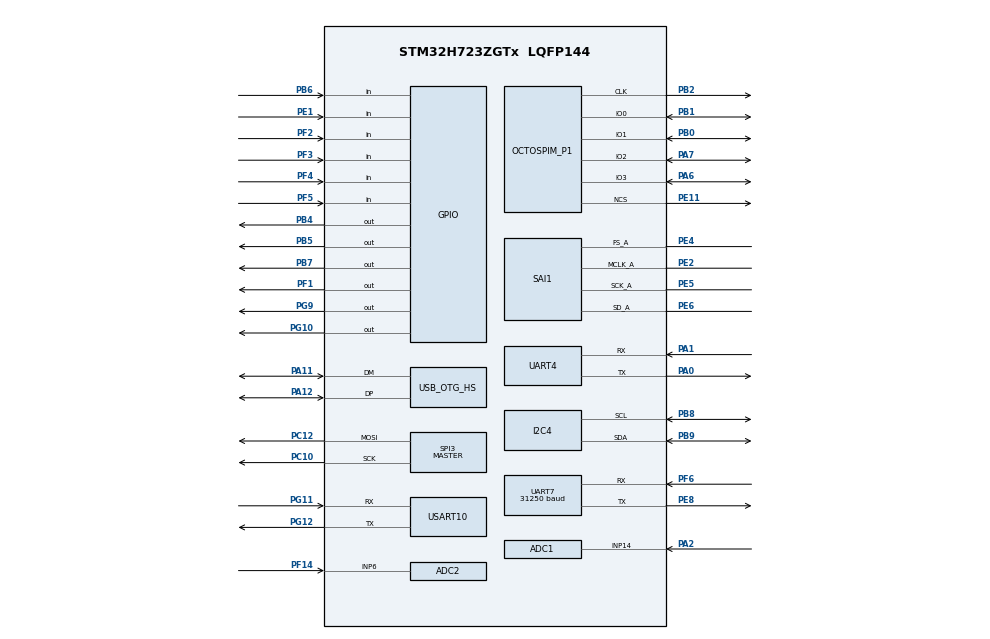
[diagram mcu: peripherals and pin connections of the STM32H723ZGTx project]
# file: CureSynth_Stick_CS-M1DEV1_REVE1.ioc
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ADC1.Channel-0\#ChannelRegularConversion=ADC_CHANNEL_14
ADC1.ClockPrescaler=ADC_CLOCK_ASYNC_DIV8
ADC1.ContinuousConvMode=ENABLE
ADC1.ConversionDataManagement=ADC_CONVERSIONDATA_DMA_CIRCULAR
ADC1.NbrOfConversionFlag=1
ADC1.OffsetNumber-0\#ChannelRegularConversion=ADC_OFFSET_NONE
ADC1.OffsetSignedSaturation-0\#ChannelRegularConversion=DISABLE
ADC1.OversamplingMode=ENABLE
ADC1.Rank-0\#ChannelRegularConversion=1
ADC1.Ratio=16
ADC1.Resolution=ADC_RESOLUTION_12B
ADC1.RightBitShift=ADC_RIGHTBITSHIFT_4
ADC1.SamplingTime-0\#ChannelRegularConversion=ADC_SAMPLETIME_387CYCLES_5
ADC1.master=1
ADC2.Channel-1\#ChannelRegularConversion=ADC_CHANNEL_6
ADC2.ClockPrescaler=ADC_CLOCK_ASYNC_DIV8
ADC2.ContinuousConvMode=ENABLE
ADC2.ConversionDataManagement=ADC_CONVERSIONDATA_DMA_CIRCULAR
ADC2.NbrOfConversionFlag=1
ADC2.OffsetNumber-1\#ChannelRegularConversion=ADC_OFFSET_NONE
ADC2.OffsetSignedSaturation-1\#ChannelRegularConversion=DISABLE
ADC2.OversamplingMode=ENABLE
ADC2.Rank-1\#ChannelRegularConversion=1
ADC2.Ratio=16
ADC2.Resolution=ADC_RESOLUTION_12B
ADC2.RightBitShift=ADC_RIGHTBITSHIFT_4
ADC2.SamplingTime-1\#ChannelRegularConversion=ADC_SAMPLETIME_387CYCLES_5
CORTEX_M7.CPU_DCache=Enabled
CORTEX_M7.CPU_ICache=Enabled
Dma.ADC1.3.Direction=DMA_PERIPH_TO_MEMORY
Dma.ADC1.3.EventEnable=DISABLE
Dma.ADC1.3.FIFOMode=DMA_FIFOMODE_DISABLE
Dma.ADC1.3.Instance=DMA1_Stream2
Dma.ADC1.3.MemDataAlignment=DMA_MDATAALIGN_HALFWORD
Dma.ADC1.3.MemInc=DMA_MINC_ENABLE
Dma.ADC1.3.Mode=DMA_CIRCULAR
Dma.ADC1.3.PeriphDataAlignment=DMA_PDATAALIGN_HALFWORD
Dma.ADC1.3.PeriphInc=DMA_PINC_DISABLE
Dma.ADC1.3.Polarity=HAL_DMAMUX_REQ_GEN_RISING
Dma.ADC1.3.Priority=DMA_PRIORITY_LOW
Dma.ADC1.3.RequestNumber=1
Dma.ADC1.3.SignalID=NONE
Dma.ADC1.3.SyncEnable=DISABLE
Dma.ADC1.3.SyncPolarity=HAL_DMAMUX_SYNC_NO_EVENT
Dma.ADC1.3.SyncRequestNumber=1
Dma.ADC1.3.SyncSignalID=NONE
Dma.ADC2.2.Direction=DMA_PERIPH_TO_MEMORY
Dma.ADC2.2.EventEnable=DISABLE
Dma.ADC2.2.FIFOMode=DMA_FIFOMODE_DISABLE
Dma.ADC2.2.Instance=DMA1_Stream1
Dma.ADC2.2.MemDataAlignment=DMA_MDATAALIGN_HALFWORD
Dma.ADC2.2.MemInc=DMA_MINC_ENABLE
Dma.ADC2.2.Mode=DMA_CIRCULAR
Dma.ADC2.2.PeriphDataAlignment=DMA_PDATAALIGN_HALFWORD
Dma.ADC2.2.PeriphInc=DMA_PINC_DISABLE
Dma.ADC2.2.Polarity=HAL_DMAMUX_REQ_GEN_RISING
Dma.ADC2.2.Priority=DMA_PRIORITY_LOW
Dma.ADC2.2.RequestNumber=1
Dma.ADC2.2.SignalID=NONE
Dma.ADC2.2.SyncEnable=DISABLE
Dma.ADC2.2.SyncPolarity=HAL_DMAMUX_SYNC_NO_EVENT
Dma.ADC2.2.SyncRequestNumber=1
Dma.ADC2.2.SyncSignalID=NONE
Dma.MEMTOMEM.4.Direction=DMA_MEMORY_TO_MEMORY
Dma.MEMTOMEM.4.EventEnable=DISABLE
Dma.MEMTOMEM.4.FIFOMode=DMA_FIFOMODE_ENABLE
Dma.MEMTOMEM.4.FIFOThreshold=DMA_FIFO_THRESHOLD_HALFFULL
Dma.MEMTOMEM.4.Instance=DMA1_Stream0
Dma.MEMTOMEM.4.MemBurst=DMA_MBURST_SINGLE
Dma.MEMTOMEM.4.MemDataAlignment=DMA_MDATAALIGN_BYTE
Dma.MEMTOMEM.4.MemInc=DMA_MINC_ENABLE
Dma.MEMTOMEM.4.Mode=DMA_NORMAL
Dma.MEMTOMEM.4.PeriphBurst=DMA_PBURST_SINGLE
Dma.MEMTOMEM.4.PeriphDataAlignment=DMA_PDATAALIGN_BYTE
Dma.MEMTOMEM.4.PeriphInc=DMA_PINC_ENABLE
Dma.MEMTOMEM.4.Polarity=HAL_DMAMUX_REQ_GEN_RISING
Dma.MEMTOMEM.4.Priority=DMA_PRIORITY_MEDIUM
Dma.MEMTOMEM.4.RequestNumber=1
Dma.MEMTOMEM.4.SignalID=NONE
Dma.MEMTOMEM.4.SyncEnable=DISABLE
Dma.MEMTOMEM.4.SyncPolarity=HAL_DMAMUX_SYNC_NO_EVENT
Dma.MEMTOMEM.4.SyncRequestNumber=1
Dma.MEMTOMEM.4.SyncSignalID=NONE
Dma.MEMTOMEM.5.Direction=DMA_MEMORY_TO_MEMORY
Dma.MEMTOMEM.5.EventEnable=DISABLE
Dma.MEMTOMEM.5.FIFOMode=DMA_FIFOMODE_ENABLE
Dma.MEMTOMEM.5.FIFOThreshold=DMA_FIFO_THRESHOLD_HALFFULL
Dma.MEMTOMEM.5.Instance=DMA1_Stream3
Dma.MEMTOMEM.5.MemBurst=DMA_MBURST_SINGLE
Dma.MEMTOMEM.5.MemDataAlignment=DMA_MDATAALIGN_BYTE
Dma.MEMTOMEM.5.MemInc=DMA_MINC_ENABLE
Dma.MEMTOMEM.5.Mode=DMA_NORMAL
Dma.MEMTOMEM.5.PeriphBurst=DMA_PBURST_SINGLE
Dma.MEMTOMEM.5.PeriphDataAlignment=DMA_PDATAALIGN_BYTE
Dma.MEMTOMEM.5.PeriphInc=DMA_PINC_ENABLE
Dma.MEMTOMEM.5.Polarity=HAL_DMAMUX_REQ_GEN_RISING
Dma.MEMTOMEM.5.Priority=DMA_PRIORITY_MEDIUM
Dma.MEMTOMEM.5.RequestNumber=1
Dma.MEMTOMEM.5.SignalID=NONE
Dma.MEMTOMEM.5.SyncEnable=DISABLE
Dma.MEMTOMEM.5.SyncPolarity=HAL_DMAMUX_SYNC_NO_EVENT
Dma.MEMTOMEM.5.SyncRequestNumber=1
Dma.MEMTOMEM.5.SyncSignalID=NONE
Dma.Request0=SPI3_TX
Dma.Request1=SAI1_A
Dma.Request2=ADC2
Dma.Request3=ADC1
Dma.Request4=MEMTOMEM
Dma.Request5=MEMTOMEM
Dma.Request6=UART7_RX
Dma.SAI1_A.1.Direction=DMA_MEMORY_TO_PERIPH
Dma.SAI1_A.1.EventEnable=DISABLE
Dma.SAI1_A.1.FIFOMode=DMA_FIFOMODE_DISABLE
Dma.SAI1_A.1.Instance=DMA2_Stream6
Dma.SAI1_A.1.MemDataAlignment=DMA_MDATAALIGN_HALFWORD
Dma.SAI1_A.1.MemInc=DMA_MINC_ENABLE
Dma.SAI1_A.1.Mode=DMA_CIRCULAR
Dma.SAI1_A.1.PeriphDataAlignment=DMA_PDATAALIGN_HALFWORD
Dma.SAI1_A.1.PeriphInc=DMA_PINC_DISABLE
Dma.SAI1_A.1.Polarity=HAL_DMAMUX_REQ_GEN_RISING
Dma.SAI1_A.1.Priority=DMA_PRIORITY_MEDIUM
Dma.SAI1_A.1.RequestNumber=1
Dma.SAI1_A.1.SignalID=NONE
Dma.SAI1_A.1.SyncEnable=DISABLE
Dma.SAI1_A.1.SyncPolarity=HAL_DMAMUX_SYNC_NO_EVENT
Dma.SAI1_A.1.SyncRequestNumber=1
Dma.SAI1_A.1.SyncSignalID=NONE
Dma.SPI3_TX.0.Direction=DMA_MEMORY_TO_PERIPH
Dma.SPI3_TX.0.EventEnable=DISABLE
Dma.SPI3_TX.0.FIFOMode=DMA_FIFOMODE_ENABLE
Dma.SPI3_TX.0.FIFOThreshold=DMA_FIFO_THRESHOLD_FULL
Dma.SPI3_TX.0.Instance=DMA1_Stream5
Dma.SPI3_TX.0.MemBurst=DMA_MBURST_SINGLE
Dma.SPI3_TX.0.MemDataAlignment=DMA_MDATAALIGN_HALFWORD
Dma.SPI3_TX.0.MemInc=DMA_MINC_ENABLE
Dma.SPI3_TX.0.Mode=DMA_NORMAL
Dma.SPI3_TX.0.PeriphBurst=DMA_PBURST_SINGLE
Dma.SPI3_TX.0.PeriphDataAlignment=DMA_PDATAALIGN_HALFWORD
Dma.SPI3_TX.0.PeriphInc=DMA_PINC_DISABLE
Dma.SPI3_TX.0.Polarity=HAL_DMAMUX_REQ_GEN_RISING
Dma.SPI3_TX.0.Priority=DMA_PRIORITY_LOW
Dma.SPI3_TX.0.RequestNumber=1
Dma.SPI3_TX.0.SignalID=NONE
Dma.SPI3_TX.0.SyncEnable=DISABLE
Dma.SPI3_TX.0.SyncPolarity=HAL_DMAMUX_SYNC_NO_EVENT
Dma.SPI3_TX.0.SyncRequestNumber=1
Dma.SPI3_TX.0.SyncSignalID=NONE
Dma.UART7_RX.6.Direction=DMA_PERIPH_TO_MEMORY
Dma.UART7_RX.6.EventEnable=DISABLE
Dma.UART7_RX.6.FIFOMode=DMA_FIFOMODE_DISABLE
Dma.UART7_RX.6.Instance=DMA1_Stream4
Dma.UART7_RX.6.MemDataAlignment=DMA_MDATAALIGN_BYTE
Dma.UART7_RX.6.MemInc=DMA_MINC_ENABLE
Dma.UART7_RX.6.Mode=DMA_NORMAL
Dma.UART7_RX.6.PeriphDataAlignment=DMA_PDATAALIGN_BYTE
Dma.UART7_RX.6.PeriphInc=DMA_PINC_DISABLE
Dma.UART7_RX.6.Polarity=HAL_DMAMUX_REQ_GEN_RISING
Dma.UART7_RX.6.Priority=DMA_PRIORITY_LOW
Dma.UART7_RX.6.RequestNumber=1
Dma.UART7_RX.6.SignalID=NONE
Dma.UART7_RX.6.SyncEnable=DISABLE
Dma.UART7_RX.6.SyncPolarity=HAL_DMAMUX_SYNC_NO_EVENT
Dma.UART7_RX.6.SyncRequestNumber=1
Dma.UART7_RX.6.SyncSignalID=NONE
I2C4.Speed=80
I2C4.Timing=0x60404DA4
IWDG1.Prescaler=IWDG_PRESCALER_16
Mcu.Family=STM32H7
Mcu.Name=STM32H723ZGTx
Mcu.Package=LQFP144
Mdma.MDMA_Channel0.DMA1_Stream0_TC.0.BlockCount=0
Mdma.MDMA_Channel0.DMA1_Stream0_TC.0.BlockDataLength=0
Mdma.MDMA_Channel0.DMA1_Stream0_TC.0.BufferTransferLength=1
Mdma.MDMA_Channel0.DMA1_Stream0_TC.0.CircularMode=MDMA_LINEAR_LIST
Mdma.MDMA_Channel0.DMA1_Stream0_TC.0.DataAlignment=MDMA_DATAALIGN_PACKENABLE
Mdma.MDMA_Channel0.DMA1_Stream0_TC.0.DestBlockAddressOffset=0
Mdma.MDMA_Channel0.DMA1_Stream0_TC.0.DestBurst=MDMA_DEST_BURST_SINGLE
Mdma.MDMA_Channel0.DMA1_Stream0_TC.0.DestDataSize=MDMA_DEST_DATASIZE_BYTE
Mdma.MDMA_Channel0.DMA1_Stream0_TC.0.DestinationInc=MDMA_DEST_INC_BYTE
Mdma.MDMA_Channel0.DMA1_Stream0_TC.0.DstAddress=0
Mdma.MDMA_Channel0.DMA1_Stream0_TC.0.Endianness=MDMA_LITTLE_ENDIANNESS_PRESERVE
Mdma.MDMA_Channel0.DMA1_Stream0_TC.0.Instance=MDMA_Channel0
Mdma.MDMA_Channel0.DMA1_Stream0_TC.0.MaskAddress=0
Mdma.MDMA_Channel0.DMA1_Stream0_TC.0.MaskData=0
Mdma.MDMA_Channel0.DMA1_Stream0_TC.0.Priority=MDMA_PRIORITY_LOW
Mdma.MDMA_Channel0.DMA1_Stream0_TC.0.Rank=First
Mdma.MDMA_Channel0.DMA1_Stream0_TC.0.SourceBlockAddressOffset=0
Mdma.MDMA_Channel0.DMA1_Stream0_TC.0.SourceBurst=MDMA_SOURCE_BURST_SINGLE
Mdma.MDMA_Channel0.DMA1_Stream0_TC.0.SourceDataSize=MDMA_SRC_DATASIZE_BYTE
Mdma.MDMA_Channel0.DMA1_Stream0_TC.0.SourceInc=MDMA_SRC_INC_BYTE
Mdma.MDMA_Channel0.DMA1_Stream0_TC.0.SrcAddress=0
Mdma.MDMA_Channel0.DMA1_Stream0_TC.0.TransferTriggerMode=MDMA_BUFFER_TRANSFER
Mdma.MDMA_Channel0.DMA1_Stream3_TC.1.BlockCount=0
Mdma.MDMA_Channel0.DMA1_Stream3_TC.1.BlockDataLength=0
Mdma.MDMA_Channel0.DMA1_Stream3_TC.1.BufferTransferLength=1
Mdma.MDMA_Channel0.DMA1_Stream3_TC.1.CircularMode=MDMA_LINEAR_LIST
Mdma.MDMA_Channel0.DMA1_Stream3_TC.1.DataAlignment=MDMA_DATAALIGN_PACKENABLE
Mdma.MDMA_Channel0.DMA1_Stream3_TC.1.DestBlockAddressOffset=0
Mdma.MDMA_Channel0.DMA1_Stream3_TC.1.DestBurst=MDMA_DEST_BURST_SINGLE
Mdma.MDMA_Channel0.DMA1_Stream3_TC.1.DestDataSize=MDMA_DEST_DATASIZE_BYTE
Mdma.MDMA_Channel0.DMA1_Stream3_TC.1.DestinationInc=MDMA_DEST_INC_BYTE
Mdma.MDMA_Channel0.DMA1_Stream3_TC.1.DstAddress=0
Mdma.MDMA_Channel0.DMA1_Stream3_TC.1.Endianness=MDMA_LITTLE_ENDIANNESS_PRESERVE
Mdma.MDMA_Channel0.DMA1_Stream3_TC.1.Instance=MDMA_Channel0
Mdma.MDMA_Channel0.DMA1_Stream3_TC.1.MaskAddress=0
Mdma.MDMA_Channel0.DMA1_Stream3_TC.1.MaskData=0
Mdma.MDMA_Channel0.DMA1_Stream3_TC.1.Priority=MDMA_PRIORITY_LOW
Mdma.MDMA_Channel0.DMA1_Stream3_TC.1.Rank=Last
Mdma.MDMA_Channel0.DMA1_Stream3_TC.1.SourceBlockAddressOffset=0
Mdma.MDMA_Channel0.DMA1_Stream3_TC.1.SourceBurst=MDMA_SOURCE_BURST_SINGLE
Mdma.MDMA_Channel0.DMA1_Stream3_TC.1.SourceDataSize=MDMA_SRC_DATASIZE_BYTE
Mdma.MDMA_Channel0.DMA1_Stream3_TC.1.SourceInc=MDMA_SRC_INC_BYTE
Mdma.MDMA_Channel0.DMA1_Stream3_TC.1.SrcAddress=0
Mdma.MDMA_Channel0.DMA1_Stream3_TC.1.TransferTriggerMode=MDMA_BUFFER_TRANSFER
Mdma.MDMA_Channel0.DMA1_Stream3_TC.1.node=node_mdma_channel40_dma1_stream3_tc_1
Mdma.MDMA_Channel0.DMA1_Stream3_TC.1.pNewNode=node_mdma_channel40_dma1_stream3_tc_1
Mdma.MDMA_Channel0.Request0=DMA1_Stream0_TC
Mdma.MDMA_Channel0.Request1=DMA1_Stream3_TC
Mdma.MDMA_Channel0.RequestsNb=2
Mdma.RequestSet0=MDMA_Channel0
Mdma.RequestSetsNb=1
NVIC.DMA1_Stream1_IRQn=true\:3\:0\:true\:false\:true\:false\:true\:true
NVIC.DMA1_Stream2_IRQn=true\:3\:0\:true\:false\:true\:false\:true\:true
NVIC.DMA1_Stream4_IRQn=true\:0\:0\:false\:false\:true\:false\:true\:true
NVIC.DMA1_Stream5_IRQn=true\:0\:0\:false\:false\:true\:false\:true\:true
NVIC.DMA2_Stream6_IRQn=true\:0\:0\:false\:false\:true\:false\:true\:true
NVIC.I2C4_EV_IRQn=true\:3\:0\:true\:false\:true\:true\:true\:true
NVIC.MDMA_IRQn=true\:0\:0\:false\:false\:true\:false\:true\:true
NVIC.OTG_HS_IRQn=true\:0\:0\:false\:false\:true\:false\:true\:true
NVIC.PriorityGroup=NVIC_PRIORITYGROUP_2
NVIC.SPI3_IRQn=true\:0\:0\:false\:false\:true\:true\:true\:true
NVIC.TIM16_IRQn=true\:1\:1\:true\:false\:true\:true\:true\:true
NVIC.TIM17_IRQn=true\:0\:1\:false\:false\:true\:true\:true\:true
NVIC.TIM6_DAC_IRQn=true\:0\:2\:false\:false\:true\:true\:true\:true
NVIC.TIM7_IRQn=true\:0\:2\:false\:false\:true\:true\:true\:true
NVIC.UART7_IRQn=true\:0\:2\:false\:false\:true\:true\:true\:true
OCTOSPI1.ChipSelectHighTime=3
OCTOSPI1.ClockPrescaler=1
OCTOSPI1.DeviceSize=21
OCTOSPI1.FifoThreshold=1
OCTOSPI1.Refresh=10
OCTOSPI1.SampleShifting=HAL_OSPI_SAMPLE_SHIFTING_HALFCYCLE
PA0.Mode=Asynchronous
PA0.Signal=UART4_TX
PA1.Mode=Asynchronous
PA1.Signal=UART4_RX
PA11.Mode=Device_Only_FS
PA11.Signal=USB_OTG_HS_DM
PA12.Mode=Device_Only_FS
PA12.Signal=USB_OTG_HS_DP
PA13(JTMS/SWDIO).Mode=Trace_Asynchronous_SW
PA13(JTMS/SWDIO).Signal=DEBUG_JTMS-SWDIO
PA14(JTCK/SWCLK).Mode=Trace_Asynchronous_SW
PA14(JTCK/SWCLK).Signal=DEBUG_JTCK-SWCLK
PA2.Signal=ADCx_INP14
PA6.GPIO_PuPd=GPIO_PULLDOWN
PA6.Mode=OCTOSPI1_IOL_Port1L
PA6.Signal=OCTOSPIM_P1_IO3
PA7.GPIO_PuPd=GPIO_PULLDOWN
PA7.Mode=OCTOSPI1_IOL_Port1L
PA7.Signal=OCTOSPIM_P1_IO2
PB0.GPIO_PuPd=GPIO_PULLDOWN
PB0.Mode=OCTOSPI1_IOL_Port1L
PB0.Signal=OCTOSPIM_P1_IO1
PB1.GPIO_PuPd=GPIO_PULLDOWN
PB1.Mode=OCTOSPI1_IOL_Port1L
PB1.Signal=OCTOSPIM_P1_IO0
PB2.GPIO_PuPd=GPIO_PULLDOWN
PB2.GPIO_Speed_High_Default=GPIO_SPEED_FREQ_HIGH
PB2.Mode=O1_P1_CLK
PB2.Signal=OCTOSPIM_P1_CLK
PB3(JTDO/TRACESWO).Mode=Trace_Asynchronous_SW
PB3(JTDO/TRACESWO).Signal=DEBUG_JTDO-SWO
PB4(NJTRST).GPIO_PuPd=GPIO_PULLDOWN
PB4(NJTRST).Signal=GPIO_Output
PB5.Signal=GPIO_Output
PB6.Signal=GPIO_Input
PB7.Signal=GPIO_Output
PB8.GPIO_Pu=GPIO_PULLUP
PB8.GPIO_PuPd=GPIO_PULLUP
PB8.GPIO_Speed=GPIO_SPEED_FREQ_MEDIUM
PB8.Mode=I2C
PB8.Signal=I2C4_SCL
PB9.GPIO_Pu=GPIO_PULLUP
PB9.GPIO_PuPd=GPIO_PULLUP
PB9.GPIO_Speed=GPIO_SPEED_FREQ_MEDIUM
PB9.Mode=I2C
PB9.Signal=I2C4_SDA
PC10.GPIO_PuPd=GPIO_NOPULL
PC10.GPIO_Speed=GPIO_SPEED_FREQ_VERY_HIGH
PC10.Mode=TX_Only_Simplex_Unidirect_Master
PC10.Signal=SPI3_SCK
PC12.GPIO_PuPd=GPIO_NOPULL
PC12.GPIO_Speed=GPIO_SPEED_FREQ_VERY_HIGH
PC12.Mode=TX_Only_Simplex_Unidirect_Master
PC12.Signal=SPI3_MOSI
PE1.Signal=GPIO_Input
PE11.GPIO_PuPd=GPIO_PULLUP
PE11.Mode=OCTOSPI1_Port1_NCS
PE11.Signal=OCTOSPIM_P1_NCS
PE2.Mode=SAI_A_MasterWithClock
PE2.Signal=SAI1_MCLK_A
PE4.Mode=SAI_A_MasterWithClock
PE4.Signal=SAI1_FS_A
PE5.GPIO_PuPd=GPIO_PULLDOWN
PE5.Mode=SAI_A_MasterWithClock
PE5.Signal=SAI1_SCK_A
PE6.Mode=SAI_A_MasterWithClock
PE6.Signal=SAI1_SD_A
PE8.Mode=Asynchronous
PE8.Signal=UART7_TX
PF1.Signal=GPIO_Output
PF14.Mode=IN6-Single-Ended
PF14.Signal=ADC2_INP6
PF2.Signal=GPIO_Input
PF3.Signal=GPIO_Input
PF4.Signal=GPIO_Input
PF5.Signal=GPIO_Input
PF6.GPIO_PuPd=GPIO_NOPULL
PF6.Mode=Asynchronous
PF6.Signal=UART7_RX
PG10.Signal=GPIO_Output
PG11.Mode=Asynchronous
PG11.Signal=USART10_RX
PG12.Mode=Asynchronous
PG12.Signal=USART10_TX
PG9.Signal=GPIO_Output
PH0-OSC_IN.Mode=HSE-External-Clock-Source
PH0-OSC_IN.Signal=RCC_OSC_IN
ProjectManager.HeapSize=0x400
ProjectManager.StackSize=0x400
ProjectManager.TargetToolchain=STM32CubeIDE
RCC.ADCFreq_Value=49152000
RCC.APB1Freq_Value=137472000
RCC.APB2Freq_Value=137472000
RCC.APB3Freq_Value=137472000
RCC.APB4Freq_Value=137472000
RCC.CortexFreq_Value=549888000
RCC.DIVM1=4
RCC.DIVM2=8
RCC.DIVM3=4
RCC.DIVN1=179
RCC.DIVN2=192
RCC.DIVN3=125
RCC.DIVP1=1
RCC.DIVP2=6
RCC.DIVQ1=7
RCC.DIVQ2=3
RCC.DIVQ3=8
RCC.DIVR1=7
RCC.DIVR2=4
RCC.EnbaleCSS=false
RCC.HCLKFreq_Value=137472000
RCC.HPRE=RCC_HCLK_DIV4
RCC.HSE_VALUE=12288000
RCC.PLLFRACN=0
RCC.PLLSourceVirtual=RCC_PLLSOURCE_HSE
RCC.QSPICLockSelection=RCC_OSPICLKSOURCE_PLL2
RCC.RNGCLockSelection=RCC_RNGCLKSOURCE_PLL
RCC.SAI1CLockSelection=RCC_SAI1CLKSOURCE_PLL2
RCC.SYSCLKFreq_VALUE=549888000
RCC.SYSCLKSource=RCC_SYSCLKSOURCE_PLLCLK
RCC.USART16CLockSelection=RCC_USART16910CLKSOURCE_PLL3
RCC.USART234578CLockSelection=RCC_USART234578CLKSOURCE_PLL3
RCC.USBCLockSelection=RCC_USBCLKSOURCE_PLL3
RCC.USBFreq_Value=48000000
RCC.VDD_VALUE=1.8
RNG.ClockErrorDetection=RNG_CED_DISABLE
SAI1.AudioFrequency-SAI_A_MasterWithClock=SAI_AUDIO_FREQUENCY_48K
SAI1.ErrorAudioFreq-SAI_A_MasterWithClock=0.0 %
SAI1.InitProtocol-SAI_A_MasterWithClock=Enable
SAI1.Instance-SAI_A_MasterWithClock=SAI$Index_Block_A
SAI1.MckOutput-SAI_A_MasterWithClock=SAI_MCK_OUTPUT_ENABLE
SAI1.RealAudioFreq-SAI_A_MasterWithClock=48.0 KHz
SAI1.VirtualMode-SAI_A_MasterWithClock=VM_MASTER
SAI1.VirtualProtocol-SAI_A_BASIC=VM_BASIC_PROTOCOL
SH.ADCx_INP14.0=ADC1_INP14,IN14-Single-Ended
SPI3.BaudRatePrescaler=SPI_BAUDRATEPRESCALER_2
SPI3.CalculateBaudRate=39.277714 MBits/s
SPI3.DataSize=SPI_DATASIZE_16BIT
SPI3.Direction=SPI_DIRECTION_2LINES_TXONLY
SPI3.Mode=SPI_MODE_MASTER
SPI3.VirtualType=VM_MASTER
TIM16.Period=61
TIM16.Prescaler=178
TIM17.Period=15
TIM17.Prescaler=178
TIM17.RepetitionCounter=0
TIM6.Period=2684
TIM6.Prescaler=511
TIM7.Period=15
TIM7.Prescaler=178
UART7.AutoBaudRateEnableParam=UART_ADVFEATURE_AUTOBAUDRATE_DISABLE
UART7.BaudRate=31250
UART7.ClockPrescaler=PRESCALER_DIV2
UART7.Mode=MODE_RX
UART7.OneBitSampling=UART_ONE_BIT_SAMPLE_ENABLE
UART7.OverSampling=UART_OVERSAMPLING_8
UART7.RxPinLevelInvertParam=UART_ADVFEATURE_RXINV_DISABLE
USART10.VirtualMode-Asynchronous=VM_ASYNC
USB_DEVICE.CLASS_NAME_HS=HID
USB_DEVICE.CONFIGURATION_STRING_HID_HS=MIDI Config
USB_DEVICE.INTERFACE_STRING_HID_HS=MIDI Interface
USB_DEVICE.LANGID_STRING=1041
USB_DEVICE.MANUFACTURER_STRING=CureSeries(TM)
USB_DEVICE.PID_HID_HS=0x42e5
USB_DEVICE.PRODUCT_STRING_HID_HS=CureSynth_mini
USB_DEVICE.VID=0x20A0
USB_DEVICE.VirtualMode=Hid
USB_DEVICE.VirtualModeHS=Hid_HS
USB_OTG_HS.Sof_enable-Device_Only_FS=DISABLE
USB_OTG_HS.VirtualMode-Device_Only_FS=Device_Only_FS
VP_IWDG1_VS_IWDG.Mode=IWDG_Activate
VP_OCTOSPI1_VS_quad.Mode=quad_mode
VP_RNG_VS_RNG.Mode=RNG_Activate
VP_SAI1_VP_$IpInstance_SAIA_SAI_BASIC.Mode=SAI_A_BASIC
VP_TIM16_VS_ClockSourceINT.Mode=Enable_Timer
VP_TIM16_VS_OPM.Mode=OPM_bit
VP_TIM17_VS_ClockSourceINT.Mode=Enable_Timer
VP_TIM6_VS_ClockSourceINT.Mode=Enable_Timer
VP_TIM7_VS_ClockSourceINT.Mode=Enable_Timer
VP_USB_DEVICE_VS_USB_DEVICE_HID_HS.Mode=HID_HS
board=custom

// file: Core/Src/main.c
/* USER CODE BEGIN Header */
/**
 ******************************************************************************
 * @file           : main.c
 * @brief          : Main program body
 ******************************************************************************
 * @attention
 *
 * <h2><center>&copy; Copyright (c) 2020 STMicroelectronics.
 * All rights reserved.</center></h2>
 *
 * This software component is licensed by ST under Ultimate Liberty license
 * SLA0044, the "License"; You may not use this file except in compliance with
 * the License. You may obtain a copy of the License at:
 *                             www.st.com/SLA0044
 *
 ******************************************************************************
 */
/* USER CODE END Header */
#include "main.h"

/* USER CODE BEGIN Includes */
#include <stdio.h>
#include <core_cm7.h>
#include "st7735s_SPI.h"
#include "ugui.h"
#include "curebuffer_static.h"
#include "usb_device.h"
#include "usbd_midi_if.h"
#include "uartmidi.h"
#include "dfilter.h"
#include "wm8960.h"
#include "curemidi.h"
#include "logo.h"

#include "curedraw.h"
#include "kanjidraw.h"
#include "fontdraw.h"

#include "sram_manage.h"

#include "curesynth_setting.h"

#include "dsp_lib/subdsp.h"

//J-Link RTT
#include "SEGGER_RTT.h"

//LR swap
#define LR_SWAP_ON

//gaming mode (will be omitted)
//#define GAMING_MODE_ON

/* USER CODE END Includes */

/* USER CODE BEGIN PD */
#define ADC_LENGTH (16)
#define FILT_WAIT_CYCLE (3000)
#define __ATTR_DTCMRAM   __attribute__ ((section(".DTCMRAM"))) __attribute__ ((aligned (4)))
#define __ATTR_ITCMRAM   __attribute__ ((section(".ITCMRAM"))) __attribute__ ((aligned (8)))
#define __ATTR_RAM_D2	__attribute__ ((section(".RAM_D2"))) __attribute__ ((aligned (4)))
#define __ATTR_RAM_D3	__attribute__ ((section(".RAM_D3"))) __attribute__ ((aligned (4)))
#define __ATTR_QSPI	   __attribute__ ((section(".QSPI_PSRAM"))) __attribute__ ((aligned (4)))

#define __ATTR_SETTING __attribute__ ((section(".setting_section"))) __attribute__ ((aligned (16)))
/* USER CODE END PD */

ADC_HandleTypeDef hadc1;
ADC_HandleTypeDef hadc2;
DMA_HandleTypeDef hdma_adc1;
DMA_HandleTypeDef hdma_adc2;

I2C_HandleTypeDef hi2c4;

IWDG_HandleTypeDef hiwdg1;

OSPI_HandleTypeDef hospi1;

RNG_HandleTypeDef hrng;

SAI_HandleTypeDef hsai_BlockA1;
DMA_HandleTypeDef hdma_sai1_a;

SPI_HandleTypeDef hspi3;
DMA_HandleTypeDef hdma_spi3_tx;

TIM_HandleTypeDef htim6;
TIM_HandleTypeDef htim7;
TIM_HandleTypeDef htim16;
TIM_HandleTypeDef htim17;

UART_HandleTypeDef huart4;
UART_HandleTypeDef huart7;
UART_HandleTypeDef huart10;
DMA_HandleTypeDef hdma_uart7_rx;

DMA_HandleTypeDef hdma_memtomem_dma1_stream0;
DMA_HandleTypeDef hdma_memtomem_dma1_stream3;
MDMA_HandleTypeDef hmdma_mdma_channel40_dma1_stream0_tc_0;
MDMA_LinkNodeTypeDef node_mdma_channel40_dma1_stream3_tc_1;
/* USER CODE BEGIN PV */
extern USBD_HandleTypeDef hUsbDeviceHS;

//for uGUI
UG_GUI gui;

//for ADC
uint16_t adc_sens_val[ADC_LENGTH] __ATTR_RAM_D2;
uint16_t adc_prev_val = 0;

uint16_t adc_sens_val_vbus[ADC_LENGTH] __ATTR_RAM_D2;
uint16_t adc_prev_val_vbus = 0;

//DAC
volatile uint32_t output_idx;
uint32_t output_started_flag;
int32_t output_err_distance;
int16_t output_buffer[OUT_BUFSIZE * 2] __ATTR_RAM_D2;
//volatile uint32_t table_idx=0;

int16_t audio_output[2];

//Displaydata
DispInfo dispinfo;

//DisplaySetting
DispSettingChangeInfo disp_change_info;

//curesynth config
const char __ATTR_SETTING curesynth_ver_string[16] = "1.0.1.a";

//firmware size, checksum(future use)
const uint32_t __ATTR_SETTING curesynth_firm[2] = {0xDEADBEEF, 0xAAAA5555};

//volume
//need conditions
//(VOL_ADC_MAX_VALUE - VOL_ADC_MIN_VALUE + 1)
//  %(VOL_9850_INDICATE_MAX + 1)
//   = 0
#define VOL_ADC_MAX_VALUE (3999)
#define VOL_ADC_MIN_VALUE (100)
#define VOL_8960_INDICATE_MAX (0x28)	//0x00-0x4F(0-40)
#define VOL_SECTION_NUM ( (VOL_ADC_MAX_VALUE - VOL_ADC_MIN_VALUE + 1) / (VOL_8960_INDICATE_MAX + 1) )
#define VOL_HYSTERESIS_VALUE (13)
#define CALC_SEC_NUM(a) ((a - VOL_ADC_MIN_VALUE) / VOL_SECTION_NUM )

typedef enum{
	TIMER_NOT_DISPLAYED, TIMER_DISPLAYED
}TimerDisplayedFlag;

typedef struct{
	uint32_t value;
	TimerDisplayedFlag status;
}Common_Timer;

#define VOL_CHANGED_TIMER_RESET_VALUE (200)//x10ms
Common_Timer vol_changed_displaying_timer = {0, TIMER_DISPLAYED};

#define TXT_CHANGED_TIMER_RESET_VALUE (200)//x10ms
Common_Timer txt_changed_displaying_timer = {0, TIMER_DISPLAYED};

typedef enum{
	VOLUME_CHANGED, VOLUME_UNCHANGED
}VolumeChangedFlag;

typedef enum{
	STATE_A, STATE_B
}VolumeState;

typedef struct{
	VolumeState volstat;
	uint8_t section_num;
}Volume;

Volume volume = {STATE_A, 0};

//VBUS sensing
//4.0V: 3250, 3.9V: 3169 3.8V:3088
#define VBUS_ADC_THR (3250)

//data watchpoint trigger
#define FP_LAR_PTR ((volatile unsigned int *) 0xe0000fb0)
// Lock Status Register lock status bit
#define DWT_LSR_SLK_Pos                1
#define DWT_LSR_SLK_Msk                (1UL << DWT_LSR_SLK_Pos)
// Lock Status Register lock availability bit
#define DWT_LSR_SLI_Pos                0
#define DWT_LSR_SLI_Msk                (1UL << DWT_LSR_SLI_Pos)
// Lock Access key, common for all
#define DWT_LAR_KEY                    0xC5ACCE55
float cpu_usage_percent = 0.0f;
float max_cpu_usage_percent = 0.0f;

//overload
#define OVERLOAD_THR_PERCENT (98.0f)
uint32_t overload_cnt = 0;

//buffer full count
uint32_t uart_buf_full_cnt = 0;
uint32_t usb_buf_full_cnt = 0;

//midi receive buffer
uint8_t midi_rx_uart __ATTR_RAM_D2;

/* USER CODE END PV */

void SystemClock_Config(void);
void PeriphCommonClock_Config(void);
static void MX_GPIO_Init(void);
static void MX_DMA_Init(void);
static void MX_ADC1_Init(void);
static void MX_ADC2_Init(void);
static void MX_I2C4_Init(void);
static void MX_IWDG1_Init(void);
static void MX_RNG_Init(void);
static void MX_SAI1_Init(void);
static void MX_SPI3_Init(void);
static void MX_TIM6_Init(void);
static void MX_TIM7_Init(void);
static void MX_USART10_UART_Init(void);
static void MX_TIM17_Init(void);
static void MX_TIM16_Init(void);
static void MX_OCTOSPI1_Init(void);
static void MX_MDMA_Init(void);
static void MX_UART4_Init(void);
static void MX_UART7_Init(void);

/* USER CODE BEGIN 0 */

//override printf
int _write(int file, char *ptr, int len){
	SEGGER_RTT_Write(0, ptr, len);
	return len;
}

//SWO print string
int32_t SWO_writeStr(char *ptr)
{
	int32_t len = strlen(ptr);

	for(uint32_t i=0; i<len; i++){
		ITM_SendChar((*ptr++));
	}

	return len;
}

//from https://stackoverflow.com/questions/38355831/measuring-clock-cycle-count-on-cortex-m7
inline void dwt_access_enable()
{
	uint32_t lsr = DWT->LSR;
	if ((lsr & DWT_LSR_SLI_Msk) != 0)
	{
		if ((lsr & DWT_LSR_SLK_Msk) != 0)    //if locked: access need unlock
			DWT->LAR = DWT_LAR_KEY;			//unlock
	}
}

inline void dwt_access_disable()
{
	uint32_t lsr = DWT->LSR;
	if ((lsr & DWT_LSR_SLI_Msk) != 0)
	{
		if ((lsr & DWT_LSR_SLK_Msk) == 0)    //if unlocked
			DWT->LAR = 0;					//lock
	}
}

inline void initCycle()
{
	dwt_access_enable();
	CoreDebug->DEMCR |= CoreDebug_DEMCR_TRCENA_Msk;
	DWT->CYCCNT = 0;
}

inline void startCycle()
{
	DWT->CTRL |= DWT_CTRL_CYCCNTENA_Msk;
	DWT->CYCCNT = 0;
}

inline void stopAndResetCycle()
{
	DWT->CTRL &= ~DWT_CTRL_CYCCNTENA_Msk;
	DWT->CYCCNT = 0;
}

inline uint32_t getCycleValue()
{
	return DWT->CYCCNT;
}

#define CPU_AVE_NUM (256)
float calcCpuUsage()
{

	float full_load_clk = (float)SystemCoreClock / (float)SAMPLE_RATE;
	return ((float)getCycleValue() * 100.0f) / full_load_clk ;
}

float calcProcessTimeMilliseconds()
{
	return ((float)getCycleValue() * 1000.0f) / (float)SystemCoreClock ;
}

inline void cureAudioProc()
{

	//generate audio
	cureSynthGetOutput(audio_output);

	//generate square test signal
	//	cureSynthGenerateTestSignalSquare(audio_output);

	//store output buffer
#ifdef LR_SWAP_ON
	output_buffer[output_idx] = audio_output[1];
	output_buffer[output_idx+1] = audio_output[0];
#else
	output_buffer[output_idx] = audio_output[0];
	output_buffer[output_idx+1] = audio_output[1];
#endif
	output_idx+=2;
	output_idx &= (OUT_BUFSIZE*2 -1);
	output_err_distance+=2;

}

//call from main
void processADCValue()
{
	adc_prev_val = dfRCFilt(adc_sens_val[0], adc_prev_val);
	adc_prev_val_vbus = dfRCFilt(adc_sens_val_vbus[0], adc_prev_val_vbus);
}

inline uint16_t getADCValue()
{
	return adc_prev_val;
}

inline uint16_t getADCValue_Vbus()
{
	return adc_prev_val_vbus;
}

VolumeChangedFlag setVolumeFromADC()
{
	uint16_t adcval = getADCValue();

	//clipping
	if(VOL_ADC_MAX_VALUE < adcval){
		adcval = VOL_ADC_MAX_VALUE;
	}else if( VOL_ADC_MIN_VALUE > adcval){
		adcval = VOL_ADC_MIN_VALUE;
	}

	switch(volume.volstat){

	case STATE_A:
		if(adcval > (VOL_ADC_MIN_VALUE + volume.section_num * VOL_SECTION_NUM + VOL_SECTION_NUM -1)){
			volume.section_num = CALC_SEC_NUM(adcval);
			return VOLUME_CHANGED;
		}else if(adcval < (VOL_ADC_MIN_VALUE + volume.section_num * VOL_SECTION_NUM -VOL_HYSTERESIS_VALUE)){
			volume.section_num = CALC_SEC_NUM(adcval);
			volume.volstat = STATE_B;
			return VOLUME_CHANGED;
		}
		break;

	case STATE_B:
		if(adcval > (VOL_ADC_MIN_VALUE + volume.section_num * VOL_SECTION_NUM + VOL_SECTION_NUM -1) + VOL_HYSTERESIS_VALUE ){
			volume.section_num = CALC_SEC_NUM(adcval);
			volume.volstat = STATE_A;
			return VOLUME_CHANGED;
		}else if(adcval < (VOL_ADC_MIN_VALUE + volume.section_num * VOL_SECTION_NUM)){
			volume.section_num = CALC_SEC_NUM(adcval);
			return VOLUME_CHANGED;
		}
		break;

	default:
		break;

	}

	return VOLUME_UNCHANGED;

}

void setVolumeIndicateTimer()
{
	vol_changed_displaying_timer.value = VOL_CHANGED_TIMER_RESET_VALUE;
	vol_changed_displaying_timer.status = TIMER_NOT_DISPLAYED;
}

void setTextIndicateTimer()
{
	txt_changed_displaying_timer.value = TXT_CHANGED_TIMER_RESET_VALUE;
	txt_changed_displaying_timer.status = TIMER_NOT_DISPLAYED;
}

void sensingVbus()
{
	uint16_t adcval = getADCValue_Vbus();

	if(VBUS_ADC_THR >= adcval){

		//mute
		wmSetVolume(0);

		//display
		cdDrawError(ERR_VOLTAGE);

		//synth
		__disable_irq();
		usbMidiBufferFlush(0);
		uartMidiBufferFlush();
		__enable_irq();

		while(1);
	}

}

FUNC_STATUS cureInit()
{

	//MIDI Initializations.
	if( FUNC_ERROR == cureMidiInit() )
	{
		return FUNC_ERROR;
	}

	//display information init
	dpinfoInit(&dispinfo);
	dpChangeInfoInit(&disp_change_info);
	return FUNC_SUCCESS;

}

void changeSystemClockToHigh()
{
	RCC_ClkInitTypeDef RCC_ClkInitStruct = {0};

	/** Initializes the CPU, AHB and APB busses clocks
	 */
	RCC_ClkInitStruct.ClockType = RCC_CLOCKTYPE_HCLK|RCC_CLOCKTYPE_SYSCLK
			|RCC_CLOCKTYPE_PCLK1|RCC_CLOCKTYPE_PCLK2
			|RCC_CLOCKTYPE_D3PCLK1|RCC_CLOCKTYPE_D1PCLK1;
	RCC_ClkInitStruct.SYSCLKSource = RCC_SYSCLKSOURCE_PLLCLK;
	RCC_ClkInitStruct.SYSCLKDivider = RCC_SYSCLK_DIV1;
	RCC_ClkInitStruct.AHBCLKDivider = RCC_HCLK_DIV4;
	RCC_ClkInitStruct.APB3CLKDivider = RCC_APB3_DIV1;
	RCC_ClkInitStruct.APB1CLKDivider = RCC_APB1_DIV1;
	RCC_ClkInitStruct.APB2CLKDivider = RCC_APB2_DIV1;
	RCC_ClkInitStruct.APB4CLKDivider = RCC_APB4_DIV1;

	if (HAL_RCC_ClockConfig(&RCC_ClkInitStruct, FLASH_LATENCY_4) != HAL_OK)
	{
		Error_Handler();
	}

	SystemCoreClockUpdate();
	HAL_Delay(50);

}

void changeSystemClockToLow()
{
	RCC_ClkInitTypeDef RCC_ClkInitStruct = {0};

	/** Initializes the CPU, AHB and APB busses clocks
	 */
	RCC_ClkInitStruct.ClockType = RCC_CLOCKTYPE_HCLK|RCC_CLOCKTYPE_SYSCLK
			|RCC_CLOCKTYPE_PCLK1|RCC_CLOCKTYPE_PCLK2
			|RCC_CLOCKTYPE_D3PCLK1|RCC_CLOCKTYPE_D1PCLK1;
	RCC_ClkInitStruct.SYSCLKSource = RCC_SYSCLKSOURCE_PLLCLK;
	RCC_ClkInitStruct.SYSCLKDivider = RCC_SYSCLK_DIV8;//if over DIV16, USB configulation is not working.
	RCC_ClkInitStruct.AHBCLKDivider = RCC_HCLK_DIV2;
	RCC_ClkInitStruct.APB3CLKDivider = RCC_APB3_DIV2;
	RCC_ClkInitStruct.APB1CLKDivider = RCC_APB1_DIV2;
	RCC_ClkInitStruct.APB2CLKDivider = RCC_APB2_DIV2;
	RCC_ClkInitStruct.APB4CLKDivider = RCC_APB4_DIV2;

	if (HAL_RCC_ClockConfig(&RCC_ClkInitStruct, FLASH_LATENCY_4) != HAL_OK)
	{
		Error_Handler();
	}

	SystemCoreClockUpdate();
	HAL_Delay(50);
}

void MPU_Config_WriteThrough()
{
	MPU_Region_InitTypeDef MPU_InitStruct;

	/* Disable the MPU */
	HAL_MPU_Disable();

	//RAM_D2 32KiB
	/* Configure the MPU attributes as WT for SRAM */
	MPU_InitStruct.Enable = MPU_REGION_ENABLE;
	MPU_InitStruct.BaseAddress = 0x30000000;
	MPU_InitStruct.Size = MPU_REGION_SIZE_32KB;
	MPU_InitStruct.AccessPermission = MPU_REGION_FULL_ACCESS;
	MPU_InitStruct.IsBufferable = MPU_ACCESS_NOT_BUFFERABLE;
	MPU_InitStruct.IsCacheable = MPU_ACCESS_CACHEABLE;
	MPU_InitStruct.IsShareable = MPU_ACCESS_SHAREABLE;
	MPU_InitStruct.Number = MPU_REGION_NUMBER0;
	MPU_InitStruct.TypeExtField = MPU_TEX_LEVEL0;
	MPU_InitStruct.SubRegionDisable = 0x00;
	MPU_InitStruct.DisableExec = MPU_INSTRUCTION_ACCESS_ENABLE;

	HAL_MPU_ConfigRegion(&MPU_InitStruct);

	//RAM_D1_VRAM1 64Kib
	/* Configure the MPU attributes as WT for SRAM */
	MPU_InitStruct.Enable = MPU_REGION_ENABLE;
	MPU_InitStruct.BaseAddress = 0x24000000;
	MPU_InitStruct.Size = MPU_REGION_SIZE_64KB;
	MPU_InitStruct.AccessPermission = MPU_REGION_FULL_ACCESS;
	MPU_InitStruct.IsBufferable = MPU_ACCESS_NOT_BUFFERABLE;
	MPU_InitStruct.IsCacheable = MPU_ACCESS_CACHEABLE;
	MPU_InitStruct.IsShareable = MPU_ACCESS_NOT_SHAREABLE;
	MPU_InitStruct.Number = MPU_REGION_NUMBER1;
	MPU_InitStruct.TypeExtField = MPU_TEX_LEVEL0;
	MPU_InitStruct.SubRegionDisable = 0x00;
	MPU_InitStruct.DisableExec = MPU_INSTRUCTION_ACCESS_ENABLE;

	HAL_MPU_ConfigRegion(&MPU_InitStruct);

	//RAM_D1_VRAM1 16Kib
	/* Configure the MPU attributes as WT for SRAM */
	MPU_InitStruct.Enable = MPU_REGION_ENABLE;
	MPU_InitStruct.BaseAddress = 0x24010000;
	MPU_InitStruct.Size = MPU_REGION_SIZE_16KB;
	MPU_InitStruct.AccessPermission = MPU_REGION_FULL_ACCESS;
	MPU_InitStruct.IsBufferable = MPU_ACCESS_NOT_BUFFERABLE;
	MPU_InitStruct.IsCacheable = MPU_ACCESS_CACHEABLE;
	MPU_InitStruct.IsShareable = MPU_ACCESS_NOT_SHAREABLE;
	MPU_InitStruct.Number = MPU_REGION_NUMBER2;
	MPU_InitStruct.TypeExtField = MPU_TEX_LEVEL0;
	MPU_InitStruct.SubRegionDisable = 0x00;
	MPU_InitStruct.DisableExec = MPU_INSTRUCTION_ACCESS_ENABLE;

	HAL_MPU_ConfigRegion(&MPU_InitStruct);

	//RAM_D1_VRAM1 4Kib
	/* Configure the MPU attributes as WT for SRAM */
	MPU_InitStruct.Enable = MPU_REGION_ENABLE;
	MPU_InitStruct.BaseAddress = 0x24014000;
	MPU_InitStruct.Size = MPU_REGION_SIZE_4KB;
	MPU_InitStruct.AccessPermission = MPU_REGION_FULL_ACCESS;
	MPU_InitStruct.IsBufferable = MPU_ACCESS_NOT_BUFFERABLE;
	MPU_InitStruct.IsCacheable = MPU_ACCESS_CACHEABLE;
	MPU_InitStruct.IsShareable = MPU_ACCESS_NOT_SHAREABLE;
	MPU_InitStruct.Number = MPU_REGION_NUMBER3;
	MPU_InitStruct.TypeExtField = MPU_TEX_LEVEL0;
	MPU_InitStruct.SubRegionDisable = 0x00;
	MPU_InitStruct.DisableExec = MPU_INSTRUCTION_ACCESS_ENABLE;

	HAL_MPU_ConfigRegion(&MPU_InitStruct);

	//External QSPI SRAM (OCTOSPI1)
	/* Configure the MPU attributes as Strongly-Ordered for OCTOSPI1*/
	MPU_InitStruct.Enable = MPU_REGION_ENABLE;
	MPU_InitStruct.BaseAddress = 0x90000000;
	MPU_InitStruct.Size = MPU_REGION_SIZE_32MB;
	MPU_InitStruct.AccessPermission = MPU_REGION_FULL_ACCESS;
	MPU_InitStruct.IsBufferable = MPU_ACCESS_NOT_BUFFERABLE;
	MPU_InitStruct.IsCacheable = MPU_ACCESS_NOT_CACHEABLE;
	MPU_InitStruct.IsShareable = MPU_ACCESS_SHAREABLE;
	MPU_InitStruct.Number = MPU_REGION_NUMBER4;
	MPU_InitStruct.TypeExtField = MPU_TEX_LEVEL0;
	MPU_InitStruct.SubRegionDisable = 0x00;
	MPU_InitStruct.DisableExec = MPU_INSTRUCTION_ACCESS_ENABLE;

	HAL_MPU_ConfigRegion(&MPU_InitStruct);

	/* Enable the MPU */
	HAL_MPU_Enable(MPU_PRIVILEGED_DEFAULT);
}

#define SRAM_TEST_SIZE (0x200000)
uint8_t test_sram_mem[SRAM_TEST_SIZE] __ATTR_QSPI;

bool sramTest()
{
	for(uint32_t i=0; i<SRAM_TEST_SIZE; i++)
	{
		test_sram_mem[i] = 0xAA;
	}

	for(uint32_t i=0; i<SRAM_TEST_SIZE; i++)
	{
		if(test_sram_mem[i] != 0xAA)
		{
			return false;
		}
	}

	for(uint32_t i=0; i<SRAM_TEST_SIZE; i++)
	{
		test_sram_mem[i] = 0x55;
	}

	for(uint32_t i=0; i<SRAM_TEST_SIZE; i++)
	{
		if(test_sram_mem[i] != 0x55)
		{
			return false;
		}
	}

	return true;
}

void drawSynthDebugInfo()
{
	static uint16_t counter = 0;
	static uint16_t state_number = 0;
	static uint16_t poly=0, poly_max = 0;

	counter++;

	if(counter <= 1000){
		return;
	}
	counter = 0;

	if(OPNUM > state_number && state_number >= 0){
		printf("OP%2d CH:%03d, CHD:%03d, NOTE:%03d, ",state_number, au_operator[state_number].ch, au_operator[state_number].ch_dcblock, au_operator[state_number].note_number);

		if(NOTE_OFF == au_operator[state_number].stat){
			printf("NOTE:OFF, ");
		}else{
			printf("NOTE: ON, ");
		}

		switch(au_operator[state_number].wav.type){
		case SINE:
			printf("TYP:SIN, ");
			break;
		case SQUARE:
			printf("TYP:SQU, ");
			break;
		case SAW:
			printf("TYP:SAW, ");
			break;
		case TRIANGLE:
			printf("TYP:TRI, ");
			break;
		case WHITE_NOISE:
			printf("TYP:WHI, ");
			break;
		case PINK_NOISE:
			printf("TYP:PNK, ");
			break;
		case PCM:
			printf("TYP:PCM, ");
			break;
		case PCM_REV:
			printf("TYP:REV, ");
			break;
		default:
			break;

		}

		switch(au_operator[state_number].env.stat){
		case ADSR_START:
			printf("S:START, ");
			break;
		case ATTACK:
			printf("S:ATTAC, ");
			break;
		case DECAY:
			printf("S:DECAY, ");
			break;
		case SUSTAIN:
			printf("S:SUSTN, ");
			break;
		case RELEASE:
			printf("S:RELAS, ");
			break;
		case ADSR_END:
			printf("S:END__, ");
			break;
		case ADSR_FINAL:
			printf("S:FINAL, ");
			break;
		default:
			break;

		}

		//		printf("PIT: %06d, ", au_operator[state_number].wav.pitch);
		printf("UNISC: %3d, ", au_operator[state_number].unisonScale);
		printf("OUT: %8ld, ", au_operator[state_number].out);
		printf("\033[0K");
		printf("\r\n");

	}else if( (OPNUM+16) > state_number && state_number >= OPNUM){

		uint16_t ch_num = (state_number - OPNUM);

		printf("CH%2d OUTL:%7d OUTR:%7d ACTIVE_OP: ", ch_num, au_out[ch_num].mono.left, au_out[ch_num].mono.right);
		for(uint16_t i=0; i<OPNUM; i++){
			if(NOTE_ON == master.channel[ch_num].operator_to_channel.ison[i]){
				printf("%d, ", i);
			}
		}
		printf("\033[0K");
		printf("\r\n");

		printf("CH%d ACTIVE_NOTE_TO_OPNUM: ", ch_num);
		for(uint16_t i=0; i<128; i++){
			if(255 != master.channel[ch_num].operator_to_note.stat[i]){
				printf("NOTE%03d OPNUM%02d, ", i, master.channel[ch_num].operator_to_note.stat[i]);
			}

		}
		printf("\033[0K");
		printf("\r\n");

	}else if( (OPNUM+16) == state_number){

		printf("CPU: %04.1f%% MAX: %04.1f%%\033[0K\r\n", cpu_usage_percent, max_cpu_usage_percent);

		poly = getUsbRxBufUsedSize(0);
		if(poly_max <= poly){
			poly_max = poly;
		}
		printf("MBUF: %d MAX: %d\033[0K\r\n",poly, poly_max);

	}else if( (OPNUM+17) == state_number){
		printf("OUTL:%07d, OUTR:%07d\033[0K\r\n", output_buffer[output_idx], output_buffer[output_idx+1]);
		printf("OL_CNT:%ld\033[0K\r\n", overload_cnt);
	}else if( (OPNUM+18) == state_number){
		printf("\033[0J");
	}else if( (OPNUM+19) == state_number){
		printf("\033[100F");
	}
	fflush(stdout);

	state_number++;
	if(state_number > (OPNUM+19)){
		state_number = 0;
	}

}

uint16_t convRGB888toRGB565(uint8_t r, uint8_t g, uint8_t b)
{
	uint16_t col = ((r >> 3)<<11) + ((g >> 2)<<5) + (b >> 3);
	return col;
}

typedef enum{
	IMG_BASE, IMG_EYE1, IMG_EYE2, IMG_EYE3, IMG_EAR1, IMG_EAR2,
}IMG_NUM;

void loadimg(IMG_NUM inum)
{
	switch(inum){

	case IMG_BASE:
		UG_FillFrame(2, 20, 159, 79, 0x0000);
		//base
		for(uint32_t logo_y=0; logo_y<IMG_R1_Y; logo_y++){
			for(uint32_t logo_x=0; logo_x<IMG_R1_X; logo_x++){
				UG_DrawPixel(2+logo_x, 25+logo_y, base_r1[logo_y][logo_x]);
			}
		}

		for(uint32_t logo_y=0; logo_y<IMG_R2_Y; logo_y++){
			for(uint32_t logo_x=0; logo_x<IMG_R2_X; logo_x++){
				UG_DrawPixel(114+logo_x, 9+logo_y, base_r2[logo_y][logo_x]);
			}
		}
		break;
	case IMG_EYE1:
		//eye
		for(uint32_t logo_y=0; logo_y<IMG_EYE_Y; logo_y++){
			for(uint32_t logo_x=0; logo_x<IMG_EYE_X; logo_x++){
				UG_DrawPixel(121+logo_x, 52+logo_y, eye_1[logo_y][logo_x]);
			}
		}
		break;
	case IMG_EYE2:
		//eye
		for(uint32_t logo_y=0; logo_y<IMG_EYE_Y; logo_y++){
			for(uint32_t logo_x=0; logo_x<IMG_EYE_X; logo_x++){
				UG_DrawPixel(121+logo_x, 52+logo_y, eye_2[logo_y][logo_x]);
			}
		}
		break;
	case IMG_EYE3:
		//eye
		for(uint32_t logo_y=0; logo_y<IMG_EYE_Y; logo_y++){
			for(uint32_t logo_x=0; logo_x<IMG_EYE_X; logo_x++){
				UG_DrawPixel(121+logo_x, 52+logo_y, eye_3[logo_y][logo_x]);
			}
		}
		break;
	case IMG_EAR1:
		//ear left
		for(uint32_t logo_y=0; logo_y<IMG_EL_Y; logo_y++){
			for(uint32_t logo_x=0; logo_x<IMG_EL_X; logo_x++){
				UG_DrawPixel(92+logo_x, 28+logo_y, eleft_1[logo_y][logo_x]);
			}
		}
		//ear right
		for(uint32_t logo_y=0; logo_y<IMG_ER_Y; logo_y++){
			for(uint32_t logo_x=0; logo_x<IMG_ER_X; logo_x++){
				UG_DrawPixel(130+logo_x, 9+logo_y, eright_1[logo_y][logo_x]);
			}
		}

		break;
	case IMG_EAR2:
		//ear left
		for(uint32_t logo_y=0; logo_y<IMG_EL_Y; logo_y++){
			for(uint32_t logo_x=0; logo_x<IMG_EL_X; logo_x++){
				UG_DrawPixel(92+logo_x, 28+logo_y, eleft_2[logo_y][logo_x]);
			}
		}
		//ear right
		for(uint32_t logo_y=0; logo_y<IMG_ER_Y; logo_y++){
			for(uint32_t logo_x=0; logo_x<IMG_ER_X; logo_x++){
				UG_DrawPixel(130+logo_x, 9+logo_y, eright_2[logo_y][logo_x]);
			}
		}
		break;
	default:
		break;
	}

}

void deviceTestSram(){

	//QSPI SRAM test
	if(!sramTest()){
		cdDrawError(ERR_SRAM);
		while(1);
	}

	UG_FillFrame(0, 0, 80, 20, C_BLACK);
	fdDrawStr(0, 0, "Initializing...");
	fdSetBackgroundColor(COL_BACKGROUND_565);
	displayUpdate();
	displayWaitDispalyTransfer();

	UG_FillScreen(C_BLACK);
}

void deviceTestDAC(){

	volatile bool errflag = false;

	wmSetGPIO(false);
	HAL_Delay(10);
	if(GPIO_PIN_RESET != HAL_GPIO_ReadPin(GPIOE, GPIO_PIN_1))
	{
		errflag |= true;
	}

	wmSetGPIO(true);
	HAL_Delay(10);
	if(GPIO_PIN_SET != HAL_GPIO_ReadPin(GPIOE, GPIO_PIN_1))
	{
		errflag |= true;
	}

	if(errflag){
		cdDrawError(ERR_DAC);
		while(1);
	}

}

#define HW_VER_READ_TIMEOUT (100)
#define HW_VER_READ_WAIT (20)
#define HW_VER_GPIOVER (uint8_t)((GPIOF->IDR &0b111100 )>>2)//PF2-PF5
uint8_t getHardwareVersion(){

	uint8_t hwver;
	uint8_t gpio_state, gpio_state_prev;

	gpio_state_prev = HW_VER_GPIOVER;

	for(uint32_t i=0; i<HW_VER_READ_TIMEOUT; i++){
		HAL_Delay(HW_VER_READ_WAIT);
		gpio_state = HW_VER_GPIOVER;

		if(gpio_state == gpio_state_prev){
			break;
		}

		gpio_state_prev = gpio_state;
	}

	switch(gpio_state){
	case 0b1000://PF2-PF5:LLLH
		hwver = 0x0A;
		break;
	default:
		hwver = 0x00;
		break;
	}

	return hwver;

}

void loadLogo_initial_drawing()
{
	char strbuf[16];

	fdSetBackgroundColor(C_BLACK);
	UG_FillScreen(C_BLACK);
	fdDrawStr(0, 0, "SW:");
	fdDrawStr(26, 0, (char *)curesynth_ver_string);
	fdDrawStr(0, 10, "HW:");
	sprintf(strbuf, "%02X", getHardwareVersion());
	fdDrawStr(26, 10, strbuf);
	loadimg(IMG_BASE);
	displayUpdate();
	displayWaitDispalyTransfer();
}

void loadLogo(){

	loadimg(IMG_BASE);
	displayUpdate();
	HAL_Delay(500);

	loadimg(IMG_EYE1);
	displayUpdate();
	HAL_Delay(50);

	loadimg(IMG_BASE);
	loadimg(IMG_EYE3);
	loadimg(IMG_EAR1);
	displayUpdate();
	HAL_Delay(50);

	loadimg(IMG_BASE);
	loadimg(IMG_EYE3);
	loadimg(IMG_EAR2);
	displayUpdate();
	HAL_Delay(50);

	loadimg(IMG_BASE);
	loadimg(IMG_EYE3);
	displayUpdate();
	HAL_Delay(50);

	loadimg(IMG_BASE);
	loadimg(IMG_EYE3);
	loadimg(IMG_EAR1);
	displayUpdate();
	HAL_Delay(50);

	loadimg(IMG_BASE);
	loadimg(IMG_EYE3);
	loadimg(IMG_EAR2);
	displayUpdate();
	HAL_Delay(50);

	loadimg(IMG_BASE);
	loadimg(IMG_EYE1);
	displayUpdate();
	HAL_Delay(50);

	loadimg(IMG_BASE);
	displayUpdate();

	displayWaitDispalyTransfer();

}

void cureReceiveAndProcessMidiMessage()
{
	uint8_t midi_dat_usb;
	uint8_t midi_dat_uart;

	//receive midi from usb
	while( FUNC_SUCCESS == midiGetFromUsbRx(0, &midi_dat_usb) ){

		HAL_IWDG_Refresh(&hiwdg1);
		if(isUsbRxBufferFull()){
			usb_buf_full_cnt++;
			__disable_irq();
			usbMidiBufferFlush(0);
			cureMidiResetFromBufferFull();
			__enable_irq();
			break;
		}
		//		  printf("0x%02x\r\n", midi_dat);
		if( cureMidiEventIsGenerated(midi_dat_usb, SRC_USB) ){// Generate MIDI event from USB buffer.
			//Analyze MIDI Message.
			cureMidiAnalyzeEvent(SRC_USB);
		}
	}

	//receive midi from uart
	while( FUNC_SUCCESS == cureUartMidiBufferDequeue(&midi_dat_uart) ){

		HAL_IWDG_Refresh(&hiwdg1);
		if(isUartRxBufferFull()){
			uart_buf_full_cnt++;
			__disable_irq();
			uartMidiBufferFlush();
			cureMidiResetFromBufferFull();
			__enable_irq();
			break;
		}
		if( cureMidiEventIsGenerated(midi_dat_uart, SRC_UART) ){// Generate MIDI event from UART buffer.
			//Analyze MIDI Message.
			cureMidiAnalyzeEvent(SRC_UART);
		}
	}

}

void activateMonitoringAudioGen()
{
	max_cpu_usage_percent = 0;
	cpu_usage_percent = 0;
	HAL_TIM_Base_Start_IT(&htim17);
}

void HAL_UART_RxCpltCallback(UART_HandleTypeDef *huart)
{
	if(huart->Instance == UART7)
	{
		cureUartMidiBufferEnqueue(&midi_rx_uart);
		HAL_UART_Receive_DMA(&huart7, &midi_rx_uart, 1);
	}
}

void HAL_UART_ErrorCallback(UART_HandleTypeDef *huart)
{
	if(huart->Instance == UART7)
	{
		HAL_UART_Receive_DMA(&huart7, &midi_rx_uart, 1);
	}
}

void HAL_I2C_MasterTxCpltCallback(I2C_HandleTypeDef *hi2c){

	if(hi2c->Instance == I2C2)
	{
		displayDMAMain();
	}else if(hi2c->Instance == I2C4)
	{
		wmSetReady();
	}

}

void HAL_I2C_MasterRxCpltCallback(I2C_HandleTypeDef *hi2c){

	if(hi2c->Instance == I2C4)
	{
		wmSetReady();
	}

}

void HAL_SPI_TxCpltCallback(SPI_HandleTypeDef *hspi){

	if(hspi->Instance == SPI3)
	{
		displaySemaphoreClear();
	}
}

void HAL_TIM_PeriodElapsedCallback(TIM_HandleTypeDef *htim)
{

	if(htim->Instance == TIM17)	//Monitoring AudioProcess Load
	{

		if((cpu_usage_percent >= OVERLOAD_THR_PERCENT) || ( calcCpuUsage() >= OVERLOAD_THR_PERCENT)){
			if(!cureMidiGetOverloadFlag()){
				//stop audio process
				HAL_TIM_Base_Stop_IT(&htim7);

				//Assert audio process restart flag
				cureMidiEnableOverloadFlag();

				cpu_usage_percent = 0;

				stopAndResetCycle();
			}
		}

	}else if(htim->Instance == TIM7)// Audio Process
	{
		startCycle();
		cureAudioProc();
		cpu_usage_percent = calcCpuUsage();
		stopAndResetCycle();
		if(max_cpu_usage_percent <= cpu_usage_percent){
			max_cpu_usage_percent = cpu_usage_percent;
		}
	}else if(htim->Instance == TIM6)	//10ms timer
	{
		if(vol_changed_displaying_timer.value > 0){
			vol_changed_displaying_timer.value--;
		}

		if(txt_changed_displaying_timer.value > 0){
			txt_changed_displaying_timer.value--;
		}

	}else if(htim->Instance == TIM16)//midi receive timer
	{

		cureReceiveAndProcessMidiMessage();

		__HAL_TIM_ENABLE_IT(&htim16, TIM_IT_UPDATE);
		__HAL_TIM_ENABLE(&htim16);
	}
}

void HAL_OSPI_TxCpltCallback(OSPI_HandleTypeDef *hospi)
{
	if(hospi->Instance == OCTOSPI1)
	{
		//		sramEndCommunication();
	}
}

void HAL_OSPI_RxCpltCallback(OSPI_HandleTypeDef *hospi)
{
	if(hospi->Instance == OCTOSPI1)
	{
		//		sramEndCommunication();
	}

}

/* USER CODE END 0 */

int main(void)
{
  /* USER CODE BEGIN 1 */

	//	__disable_irq();
	//	SCB->VTOR = 0x08020400;
	//	__enable_irq();

	MPU_Config_WriteThrough();

	//Load functions into ITCM RAM
	extern const unsigned char itcm_text_start;
	extern const unsigned char itcm_text_end;
	extern const unsigned char itcm_data;
	memcpy( (unsigned char *)(&itcm_text_start), &itcm_data, (int) (&itcm_text_end - &itcm_text_start));

  /* USER CODE END 1 */

  /* Enable I-Cache---------------------------------------------------------*/
  SCB_EnableICache();

  /* Enable D-Cache---------------------------------------------------------*/
  SCB_EnableDCache();

  /* MCU Configuration--------------------------------------------------------*/

  /* Reset of all peripherals, Initializes the Flash interface and the Systick. */
  HAL_Init();

  /* Configure the system clock */
  SystemClock_Config();

/* Configure the peripherals common clocks */
  PeriphCommonClock_Config();

  /* USER CODE BEGIN SysInit */

	//  changeSystemClockToLow();
	//inactivate IWDG in debug mode.
	//see https://stackoverflow.com/questions/32532916/disabling-the-stm32-iwdg-during-debugging
	__HAL_DBGMCU_FREEZE_IWDG1();

  /* USER CODE END SysInit */

  /* Initialize all configured peripherals */
  MX_GPIO_Init();
  MX_DMA_Init();
  MX_ADC1_Init();
  MX_ADC2_Init();
  MX_I2C4_Init();
  MX_RNG_Init();
  MX_SAI1_Init();
  MX_SPI3_Init();
  MX_TIM6_Init();
  MX_TIM7_Init();
  MX_USART10_UART_Init();
  MX_TIM17_Init();
  MX_TIM16_Init();
  MX_OCTOSPI1_Init();
  MX_MDMA_Init();
  MX_UART4_Init();
  MX_UART7_Init();
  /* USER CODE BEGIN 2 */

	//HSLV on (!!!!! only 2.5V > VDD !!!!!!!)
	HAL_SYSCFG_EnableIOSpeedOptimize();

	//Display Initialization
	displayInit();

	//Init ugui
	UG_Init(&gui, pset, VRAM_X_SIZE/2, VRAM_Y_SIZE/2);
	UG_SetBackcolor(COL_BACKGROUND_565);
	UG_SetForecolor(COL_FOREGROUND_565);
	UG_FillScreen(C_BLACK);

	UG_FontSelect(&FONT_8X12);

	displayUpdate();
	displayWaitDispalyTransfer();

	curedrawInit();

	//turn on Analog 3.3V Power
	HAL_GPIO_WritePin(GPIOB, GPIO_PIN_7, GPIO_PIN_SET);

	//debug
	fdSetForegroundColor(COL_FOREGROUND_565);
	fdSetBackgroundColor(COL_BACKGROUND_565);

	//QSPI SRAM Initialization
	if( !sramInit() ){
		//Backlight on
		dispBacklightOn();
		cdDrawError(ERR_SRAM);
		while(1);
	}

	//WM8960 DAC Init 1
	if( wmInit_process1()){
		//Backlight on
		dispBacklightOn();
		cdDrawError(ERR_DAC);
		while(1);
	}

	loadLogo_initial_drawing();
	//Backlight on
	dispBacklightOn();
	loadLogo();

	//WM8960 DAC Init 2
	if( wmInit_process2()){
		cdDrawError(ERR_DAC);
		while(1);
	}
	deviceTestDAC();

	//test sram
	deviceTestSram();

	//MIDI from UART Initializations
	if( FUNC_ERROR == cureUartMidiInit() )
	{
		UG_FillScreen(C_BLACK);
		while(1){
			cdDrawError(ERR_UARTMEM);
		}
	}

	////USB-MIDI Initialization
	//USB-MIDI buffer Init
	if(FUNC_ERROR == midiInit() ){
		UG_FillScreen(C_BLACK);
		while(1){
			cdDrawError(ERR_INITMIDI);
		}
	}

	//USB-MIDI Driver Init
	MX_USB_MIDI_INIT();

	//Wait usb configuration.
	uint32_t usb_check_cnt = 0;
	while(1){
		if(USBD_STATE_CONFIGURED == hUsbDeviceHS.dev_state){
			UG_FillScreen(C_BLACK);
			break;
		}else{
			if(usb_check_cnt >= 500){	//if usb is not configurated within 0.5s, stop waiting.
				UG_FillScreen(C_BLACK);
				break;
			}else{
				HAL_Delay(1);
				usb_check_cnt++;
			}
		}
	}

	//    changeSystemClockToHigh();

	//ADC start : need more times to stabilize ADC
	HAL_ADCEx_Calibration_Start(&hadc1, ADC_CALIB_OFFSET, ADC_SINGLE_ENDED);
	HAL_ADC_Start_DMA(&hadc1, (uint32_t *)adc_sens_val, ADC_LENGTH);

	HAL_ADCEx_Calibration_Start(&hadc2, ADC_CALIB_OFFSET, ADC_SINGLE_ENDED);
	HAL_ADC_Start_DMA(&hadc2, (uint32_t *)adc_sens_val_vbus, ADC_LENGTH);

	//Synthesizer Initialization
	if(FUNC_ERROR == cureInit() ){
		UG_FillScreen(C_BLACK);
		while(1){
			cdDrawError(ERR_INITSYN);
		}
	}

	//Init DAC buffer
	for(uint16_t i=0; i<OUT_BUFSIZE * 2; i++){
		output_buffer[i] = 0;
	}

	//init cpu usage counter
	initCycle();

	//start Audio generation timer and cpu usage counter
	HAL_TIM_Base_Start_IT(&htim7);

	//Start SAI2 and wait DAC buffer will be half-full.
	while(1)
	{
		if((output_idx) > ( OUT_BUFSIZE ) )
		{
			//start DAC
			if(HAL_OK != HAL_SAI_Transmit_DMA(&hsai_BlockA1, (uint8_t *)(output_buffer), OUT_BUFSIZE * 2))
			{
				cdDrawError(ERR_AUDIO);
				Error_Handler();
			}
			output_err_distance = 0;
			break;
		}
	}

	//cycle count active
	CoreDebug->DEMCR |= CoreDebug_DEMCR_TRCENA_Msk;
	DWT->CTRL |= DWT_CTRL_CYCCNTENA_Msk;

	//start 10ms timer
	HAL_TIM_Base_Start_IT(&htim6);

	//start Monitoring Audio Generation Load
	activateMonitoringAudioGen();

	//Volume set
	for(uint32_t j=0; j<FILT_WAIT_CYCLE; j++){
		processADCValue();
	}
	processADCValue();
	setVolumeFromADC();
	wmSetVolume(volume.section_num);

	//debug J-link RTT
	SEGGER_RTT_Init();

	//draw background
	curedrawBackgroundInit();

	//draw default text
	cdDrawText(DISP_DEFAULT_STRING);

	displayUpdate();
	displayWaitDispalyTransfer();

	//volume unmute
	wmDACUnmute();

	//IWDG activate
	//    MX_IWDG1_Init();

  /* USER CODE END 2 */

  /* Infinite loop */
  /* USER CODE BEGIN WHILE */

#define DISPLAY_INDICATE_THR (10)
	static uint32_t display_indicate_cnt = 0;
	char txt_buffer[32];
	char strbuf[32];

	//start processing midi timer
	HAL_TIM_Base_Start_IT(&htim16);

	//start MIDI message reception with interrupt.
	HAL_UART_Receive_DMA(&huart7, &midi_rx_uart, 1);

	while (1)
	{
    /* USER CODE END WHILE */

    /* USER CODE BEGIN 3 */
		HAL_IWDG_Refresh(&hiwdg1);

		drawSynthDebugInfo();

		//sensing vbus
		sensingVbus();

		static bool redraw_default_txt = false;
		static bool redraw_jpText = false;
		if(!displayisUpdating())
		{
			processADCValue();
			if(VOLUME_CHANGED == setVolumeFromADC()){
				wmSetVolume(volume.section_num);
				setVolumeIndicateTimer();
			}

			if(DISPLAY_INDICATE_THR <= display_indicate_cnt){// display indicate speed configure

				if(vol_changed_displaying_timer.value >0){

					if(TIMER_NOT_DISPLAYED == vol_changed_displaying_timer.status){
						cdDrawRotaryVolume(volume.section_num);
						vol_changed_displaying_timer.status = TIMER_DISPLAYED;
						redraw_default_txt = true;
						redraw_jpText = true;
					}

				}else{

					//get txt message
					if(cureMidiIsGetDisplayMessage(txt_buffer)){
						setTextIndicateTimer();
					}

					//get and set display setting change
					cureMidiGetDisplayChangeInfo(&disp_change_info);
					if(COL_CHANGE_NOTHING != disp_change_info.display_color_change_state){
						redraw_jpText = true;
					}
					if(redraw_jpText){
						disp_change_info.language_control_state_upper = LANG_CTRL_UPDATE;
						disp_change_info.language_control_state_lower = LANG_CTRL_UPDATE;
					}

#ifdef GAMING_MODE_ON
					disp_change_info.language_control_state_upper = LANG_CTRL_UPDATE;
					disp_change_info.language_control_state_lower = LANG_CTRL_UPDATE;
					redraw_default_txt = true;
					cdSetDisplayGamingMode();
#else

#endif

					cdSetDisplayChangeInfo(&disp_change_info);

					//draw bargraph
					cureMidiGetDisplayData(&dispinfo);
					uint8_t pk_vol[2];
					for(uint32_t i=0; i<2; i++){
						if(synth_peak_detect.prev_out[i] <= 26){//ref excel sheet
							pk_vol[i] = 0;
						}else{
							pk_vol[i] = 20 * log10f(synth_peak_detect.prev_out[i]/32768.0f) + 63;
							pk_vol[i] = roundf(pk_vol[i]);
							pk_vol[i] = __USAT(pk_vol[i] , 6);
						}
					}
					cdMakeIndicator(&dispinfo, pk_vol, output_buffer, output_idx);

					//eye-blinking animation
					cdDrawEyeBlinking();

					//draw txt message
					if(txt_changed_displaying_timer.value >0){
						if(TIMER_NOT_DISPLAYED == txt_changed_displaying_timer.status){
							cdDrawText(txt_buffer);
							txt_changed_displaying_timer.status = TIMER_DISPLAYED;
							redraw_default_txt = true;
						}

					}else{
						if(redraw_default_txt){
							cdDrawText(DISP_DEFAULT_STRING);
							redraw_default_txt = false;
						}
					}

					//draw USB indicator
					if(USBD_STATE_CONFIGURED == hUsbDeviceHS.dev_state){
						cdDrawUsbState(0);
					}else if(USBD_STATE_SUSPENDED == hUsbDeviceHS.dev_state){
						cdDrawUsbState(1);
					}else{
						cdDrawUsbState(2);
					}

				}

				static bool is_debug_display_changed;
				if(cureMidiIsDebugDisplay()){
					fdSetBackgroundColor(C_BLACK);
					fdSetForegroundColor(C_YELLOW);
					is_debug_display_changed= true;
					sprintf(strbuf, "CPU:%04.1f%% MAX:%04.1f%%", cpu_usage_percent, max_cpu_usage_percent);
					fdDrawStr(0, 0, strbuf);
					sprintf(strbuf, "L:%6d,R:%6d", output_buffer[output_idx], output_buffer[output_idx+1]);
					fdDrawStr(0, 10, strbuf);
					sprintf(strbuf, "OVLD:%03ld", overload_cnt);
					fdDrawStr(0, 22, strbuf);
					sprintf(strbuf, "FUL_USB:%04ld",usb_buf_full_cnt);
					fdDrawStr(0, 32, strbuf);
					sprintf(strbuf, "FUL_UART:%04ld",uart_buf_full_cnt);
					fdDrawStr(0, 42, strbuf);
					sprintf(strbuf, "VOL:%04d",adc_prev_val);
					fdDrawStr(0, 52, strbuf);
					sprintf(strbuf, "VBUS:%04d",adc_prev_val_vbus);
					fdDrawStr(0, 62, strbuf);
					displaySetColorNormal();
				}else{
					if(is_debug_display_changed){
						redraw_default_txt = true;
						redraw_jpText = true;
						is_debug_display_changed = false;
					}

				}

				displayUpdate();
				display_indicate_cnt = 0;
			}else{
				display_indicate_cnt++;
			}

		}

		// if overload
		if(cureMidiGetOverloadFlag()){
			overload_cnt++;

			__disable_irq();
			usbMidiBufferFlush(0);
			uartMidiBufferFlush();
			cureMidiResetFromOverload();

			//restart synth
			cureMidiDisableOverloadFlag();
			HAL_TIM_Base_Start_IT(&htim7);

			__enable_irq();
		}

	}
  /* USER CODE END 3 */
}

void SystemClock_Config(void)
{
  RCC_OscInitTypeDef RCC_OscInitStruct = {0};
  RCC_ClkInitTypeDef RCC_ClkInitStruct = {0};

  /** Supply configuration update enable
  */
  HAL_PWREx_ConfigSupply(PWR_LDO_SUPPLY);

  /** Configure the main internal regulator output voltage
  */
  __HAL_PWR_VOLTAGESCALING_CONFIG(PWR_REGULATOR_VOLTAGE_SCALE0);

  while(!__HAL_PWR_GET_FLAG(PWR_FLAG_VOSRDY)) {}

  /** Macro to configure the PLL clock source
  */
  __HAL_RCC_PLL_PLLSOURCE_CONFIG(RCC_PLLSOURCE_HSE);

  /** Initializes the RCC Oscillators according to the specified parameters
  * in the RCC_OscInitTypeDef structure.
  */
  RCC_OscInitStruct.OscillatorType = RCC_OSCILLATORTYPE_LSI|RCC_OSCILLATORTYPE_HSE;
  RCC_OscInitStruct.HSEState = RCC_HSE_BYPASS;
  RCC_OscInitStruct.LSIState = RCC_LSI_ON;
  RCC_OscInitStruct.PLL.PLLState = RCC_PLL_ON;
  RCC_OscInitStruct.PLL.PLLSource = RCC_PLLSOURCE_HSE;
  RCC_OscInitStruct.PLL.PLLM = 4;
  RCC_OscInitStruct.PLL.PLLN = 179;
  RCC_OscInitStruct.PLL.PLLP = 1;
  RCC_OscInitStruct.PLL.PLLQ = 7;
  RCC_OscInitStruct.PLL.PLLR = 7;
  RCC_OscInitStruct.PLL.PLLRGE = RCC_PLL1VCIRANGE_1;
  RCC_OscInitStruct.PLL.PLLVCOSEL = RCC_PLL1VCOWIDE;
  RCC_OscInitStruct.PLL.PLLFRACN = 0;
  if (HAL_RCC_OscConfig(&RCC_OscInitStruct) != HAL_OK)
  {
    Error_Handler();
  }

  /** Initializes the CPU, AHB and APB buses clocks
  */
  RCC_ClkInitStruct.ClockType = RCC_CLOCKTYPE_HCLK|RCC_CLOCKTYPE_SYSCLK
                              |RCC_CLOCKTYPE_PCLK1|RCC_CLOCKTYPE_PCLK2
                              |RCC_CLOCKTYPE_D3PCLK1|RCC_CLOCKTYPE_D1PCLK1;
  RCC_ClkInitStruct.SYSCLKSource = RCC_SYSCLKSOURCE_PLLCLK;
  RCC_ClkInitStruct.SYSCLKDivider = RCC_SYSCLK_DIV1;
  RCC_ClkInitStruct.AHBCLKDivider = RCC_HCLK_DIV4;
  RCC_ClkInitStruct.APB3CLKDivider = RCC_APB3_DIV1;
  RCC_ClkInitStruct.APB1CLKDivider = RCC_APB1_DIV1;
  RCC_ClkInitStruct.APB2CLKDivider = RCC_APB2_DIV1;
  RCC_ClkInitStruct.APB4CLKDivider = RCC_APB4_DIV1;

  if (HAL_RCC_ClockConfig(&RCC_ClkInitStruct, FLASH_LATENCY_1) != HAL_OK)
  {
    Error_Handler();
  }
}

void PeriphCommonClock_Config(void)
{
  RCC_PeriphCLKInitTypeDef PeriphClkInitStruct = {0};

  /** Initializes the peripherals clock
  */
  PeriphClkInitStruct.PeriphClockSelection = RCC_PERIPHCLK_OSPI|RCC_PERIPHCLK_USB
                              |RCC_PERIPHCLK_ADC|RCC_PERIPHCLK_SAI1
                              |RCC_PERIPHCLK_USART10|RCC_PERIPHCLK_UART7
                              |RCC_PERIPHCLK_UART4;
  PeriphClkInitStruct.PLL2.PLL2M = 8;
  PeriphClkInitStruct.PLL2.PLL2N = 192;
  PeriphClkInitStruct.PLL2.PLL2P = 6;
  PeriphClkInitStruct.PLL2.PLL2Q = 3;
  PeriphClkInitStruct.PLL2.PLL2R = 4;
  PeriphClkInitStruct.PLL2.PLL2RGE = RCC_PLL2VCIRANGE_0;
  PeriphClkInitStruct.PLL2.PLL2VCOSEL = RCC_PLL2VCOMEDIUM;
  PeriphClkInitStruct.PLL2.PLL2FRACN = 0;
  PeriphClkInitStruct.PLL3.PLL3M = 4;
  PeriphClkInitStruct.PLL3.PLL3N = 125;
  PeriphClkInitStruct.PLL3.PLL3P = 2;
  PeriphClkInitStruct.PLL3.PLL3Q = 8;
  PeriphClkInitStruct.PLL3.PLL3R = 2;
  PeriphClkInitStruct.PLL3.PLL3RGE = RCC_PLL3VCIRANGE_1;
  PeriphClkInitStruct.PLL3.PLL3VCOSEL = RCC_PLL3VCOWIDE;
  PeriphClkInitStruct.PLL3.PLL3FRACN = 0;
  PeriphClkInitStruct.OspiClockSelection = RCC_OSPICLKSOURCE_PLL2;
  PeriphClkInitStruct.Sai1ClockSelection = RCC_SAI1CLKSOURCE_PLL2;
  PeriphClkInitStruct.Usart234578ClockSelection = RCC_USART234578CLKSOURCE_PLL3;
  PeriphClkInitStruct.Usart16ClockSelection = RCC_USART16910CLKSOURCE_PLL3;
  PeriphClkInitStruct.UsbClockSelection = RCC_USBCLKSOURCE_PLL3;
  PeriphClkInitStruct.AdcClockSelection = RCC_ADCCLKSOURCE_PLL2;
  if (HAL_RCCEx_PeriphCLKConfig(&PeriphClkInitStruct) != HAL_OK)
  {
    Error_Handler();
  }
}

static void MX_ADC1_Init(void)
{

  ADC_MultiModeTypeDef multimode = {0};
  ADC_ChannelConfTypeDef sConfig = {0};

  /** Common config
  */
  hadc1.Instance = ADC1;
  hadc1.Init.ClockPrescaler = ADC_CLOCK_ASYNC_DIV8;
  hadc1.Init.Resolution = ADC_RESOLUTION_12B;
  hadc1.Init.ScanConvMode = ADC_SCAN_DISABLE;
  hadc1.Init.EOCSelection = ADC_EOC_SINGLE_CONV;
  hadc1.Init.LowPowerAutoWait = DISABLE;
  hadc1.Init.ContinuousConvMode = ENABLE;
  hadc1.Init.NbrOfConversion = 1;
  hadc1.Init.DiscontinuousConvMode = DISABLE;
  hadc1.Init.ExternalTrigConv = ADC_SOFTWARE_START;
  hadc1.Init.ExternalTrigConvEdge = ADC_EXTERNALTRIGCONVEDGE_NONE;
  hadc1.Init.ConversionDataManagement = ADC_CONVERSIONDATA_DMA_CIRCULAR;
  hadc1.Init.Overrun = ADC_OVR_DATA_PRESERVED;
  hadc1.Init.LeftBitShift = ADC_LEFTBITSHIFT_NONE;
  hadc1.Init.OversamplingMode = ENABLE;
  hadc1.Init.Oversampling.Ratio = 16;
  hadc1.Init.Oversampling.RightBitShift = ADC_RIGHTBITSHIFT_4;
  hadc1.Init.Oversampling.TriggeredMode = ADC_TRIGGEREDMODE_SINGLE_TRIGGER;
  hadc1.Init.Oversampling.OversamplingStopReset = ADC_REGOVERSAMPLING_CONTINUED_MODE;
  if (HAL_ADC_Init(&hadc1) != HAL_OK)
  {
    Error_Handler();
  }

  /** Configure the ADC multi-mode
  */
  multimode.Mode = ADC_MODE_INDEPENDENT;
  if (HAL_ADCEx_MultiModeConfigChannel(&hadc1, &multimode) != HAL_OK)
  {
    Error_Handler();
  }

  /** Configure Regular Channel
  */
  sConfig.Channel = ADC_CHANNEL_14;
  sConfig.Rank = ADC_REGULAR_RANK_1;
  sConfig.SamplingTime = ADC_SAMPLETIME_387CYCLES_5;
  sConfig.SingleDiff = ADC_SINGLE_ENDED;
  sConfig.OffsetNumber = ADC_OFFSET_NONE;
  sConfig.Offset = 0;
  sConfig.OffsetSignedSaturation = DISABLE;
  if (HAL_ADC_ConfigChannel(&hadc1, &sConfig) != HAL_OK)
  {
    Error_Handler();
  }

}

static void MX_ADC2_Init(void)
{

  ADC_ChannelConfTypeDef sConfig = {0};

  /** Common config
  */
  hadc2.Instance = ADC2;
  hadc2.Init.ClockPrescaler = ADC_CLOCK_ASYNC_DIV8;
  hadc2.Init.Resolution = ADC_RESOLUTION_12B;
  hadc2.Init.ScanConvMode = ADC_SCAN_DISABLE;
  hadc2.Init.EOCSelection = ADC_EOC_SINGLE_CONV;
  hadc2.Init.LowPowerAutoWait = DISABLE;
  hadc2.Init.ContinuousConvMode = ENABLE;
  hadc2.Init.NbrOfConversion = 1;
  hadc2.Init.DiscontinuousConvMode = DISABLE;
  hadc2.Init.ExternalTrigConv = ADC_SOFTWARE_START;
  hadc2.Init.ExternalTrigConvEdge = ADC_EXTERNALTRIGCONVEDGE_NONE;
  hadc2.Init.ConversionDataManagement = ADC_CONVERSIONDATA_DMA_CIRCULAR;
  hadc2.Init.Overrun = ADC_OVR_DATA_PRESERVED;
  hadc2.Init.LeftBitShift = ADC_LEFTBITSHIFT_NONE;
  hadc2.Init.OversamplingMode = ENABLE;
  hadc2.Init.Oversampling.Ratio = 16;
  hadc2.Init.Oversampling.RightBitShift = ADC_RIGHTBITSHIFT_4;
  hadc2.Init.Oversampling.TriggeredMode = ADC_TRIGGEREDMODE_SINGLE_TRIGGER;
  hadc2.Init.Oversampling.OversamplingStopReset = ADC_REGOVERSAMPLING_CONTINUED_MODE;
  if (HAL_ADC_Init(&hadc2) != HAL_OK)
  {
    Error_Handler();
  }

  /** Configure Regular Channel
  */
  sConfig.Channel = ADC_CHANNEL_6;
  sConfig.Rank = ADC_REGULAR_RANK_1;
  sConfig.SamplingTime = ADC_SAMPLETIME_387CYCLES_5;
  sConfig.SingleDiff = ADC_SINGLE_ENDED;
  sConfig.OffsetNumber = ADC_OFFSET_NONE;
  sConfig.Offset = 0;
  sConfig.OffsetSignedSaturation = DISABLE;
  if (HAL_ADC_ConfigChannel(&hadc2, &sConfig) != HAL_OK)
  {
    Error_Handler();
  }

}

static void MX_I2C4_Init(void)
{

  hi2c4.Instance = I2C4;
  hi2c4.Init.Timing = 0x60404DA4;
  hi2c4.Init.OwnAddress1 = 0;
  hi2c4.Init.AddressingMode = I2C_ADDRESSINGMODE_7BIT;
  hi2c4.Init.DualAddressMode = I2C_DUALADDRESS_DISABLE;
  hi2c4.Init.OwnAddress2 = 0;
  hi2c4.Init.OwnAddress2Masks = I2C_OA2_NOMASK;
  hi2c4.Init.GeneralCallMode = I2C_GENERALCALL_DISABLE;
  hi2c4.Init.NoStretchMode = I2C_NOSTRETCH_DISABLE;
  if (HAL_I2C_Init(&hi2c4) != HAL_OK)
  {
    Error_Handler();
  }

  /** Configure Analogue filter
  */
  if (HAL_I2CEx_ConfigAnalogFilter(&hi2c4, I2C_ANALOGFILTER_ENABLE) != HAL_OK)
  {
    Error_Handler();
  }

  /** Configure Digital filter
  */
  if (HAL_I2CEx_ConfigDigitalFilter(&hi2c4, 0) != HAL_OK)
  {
    Error_Handler();
  }

}

static void MX_IWDG1_Init(void)
{

  hiwdg1.Instance = IWDG1;
  hiwdg1.Init.Prescaler = IWDG_PRESCALER_16;
  hiwdg1.Init.Window = 4095;
  hiwdg1.Init.Reload = 4095;
  if (HAL_IWDG_Init(&hiwdg1) != HAL_OK)
  {
    Error_Handler();
  }

}

static void MX_OCTOSPI1_Init(void)
{

  OSPIM_CfgTypeDef sOspiManagerCfg = {0};

  /* OCTOSPI1 parameter configuration*/
  hospi1.Instance = OCTOSPI1;
  hospi1.Init.FifoThreshold = 1;
  hospi1.Init.DualQuad = HAL_OSPI_DUALQUAD_DISABLE;
  hospi1.Init.MemoryType = HAL_OSPI_MEMTYPE_MICRON;
  hospi1.Init.DeviceSize = 21;
  hospi1.Init.ChipSelectHighTime = 3;
  hospi1.Init.FreeRunningClock = HAL_OSPI_FREERUNCLK_DISABLE;
  hospi1.Init.ClockMode = HAL_OSPI_CLOCK_MODE_0;
  hospi1.Init.WrapSize = HAL_OSPI_WRAP_NOT_SUPPORTED;
  hospi1.Init.ClockPrescaler = 1;
  hospi1.Init.SampleShifting = HAL_OSPI_SAMPLE_SHIFTING_HALFCYCLE;
  hospi1.Init.DelayHoldQuarterCycle = HAL_OSPI_DHQC_DISABLE;
  hospi1.Init.ChipSelectBoundary = 0;
  hospi1.Init.DelayBlockBypass = HAL_OSPI_DELAY_BLOCK_BYPASSED;
  hospi1.Init.MaxTran = 0;
  hospi1.Init.Refresh = 10;
  if (HAL_OSPI_Init(&hospi1) != HAL_OK)
  {
    Error_Handler();
  }
  sOspiManagerCfg.ClkPort = 1;
  sOspiManagerCfg.NCSPort = 1;
  sOspiManagerCfg.IOLowPort = HAL_OSPIM_IOPORT_1_LOW;
  if (HAL_OSPIM_Config(&hospi1, &sOspiManagerCfg, HAL_OSPI_TIMEOUT_DEFAULT_VALUE) != HAL_OK)
  {
    Error_Handler();
  }

}

static void MX_RNG_Init(void)
{

  hrng.Instance = RNG;
  hrng.Init.ClockErrorDetection = RNG_CED_DISABLE;
  if (HAL_RNG_Init(&hrng) != HAL_OK)
  {
    Error_Handler();
  }

}

static void MX_SAI1_Init(void)
{

  hsai_BlockA1.Instance = SAI1_Block_A;
  hsai_BlockA1.Init.AudioMode = SAI_MODEMASTER_TX;
  hsai_BlockA1.Init.Synchro = SAI_ASYNCHRONOUS;
  hsai_BlockA1.Init.OutputDrive = SAI_OUTPUTDRIVE_DISABLE;
  hsai_BlockA1.Init.NoDivider = SAI_MASTERDIVIDER_ENABLE;
  hsai_BlockA1.Init.FIFOThreshold = SAI_FIFOTHRESHOLD_EMPTY;
  hsai_BlockA1.Init.AudioFrequency = SAI_AUDIO_FREQUENCY_48K;
  hsai_BlockA1.Init.SynchroExt = SAI_SYNCEXT_DISABLE;
  hsai_BlockA1.Init.MonoStereoMode = SAI_STEREOMODE;
  hsai_BlockA1.Init.CompandingMode = SAI_NOCOMPANDING;
  hsai_BlockA1.Init.TriState = SAI_OUTPUT_NOTRELEASED;
  if (HAL_SAI_InitProtocol(&hsai_BlockA1, SAI_I2S_STANDARD, SAI_PROTOCOL_DATASIZE_16BIT, 2) != HAL_OK)
  {
    Error_Handler();
  }

}

static void MX_SPI3_Init(void)
{

  /* SPI3 parameter configuration*/
  hspi3.Instance = SPI3;
  hspi3.Init.Mode = SPI_MODE_MASTER;
  hspi3.Init.Direction = SPI_DIRECTION_2LINES_TXONLY;
  hspi3.Init.DataSize = SPI_DATASIZE_16BIT;
  hspi3.Init.CLKPolarity = SPI_POLARITY_LOW;
  hspi3.Init.CLKPhase = SPI_PHASE_1EDGE;
  hspi3.Init.NSS = SPI_NSS_SOFT;
  hspi3.Init.BaudRatePrescaler = SPI_BAUDRATEPRESCALER_2;
  hspi3.Init.FirstBit = SPI_FIRSTBIT_MSB;
  hspi3.Init.TIMode = SPI_TIMODE_DISABLE;
  hspi3.Init.CRCCalculation = SPI_CRCCALCULATION_DISABLE;
  hspi3.Init.CRCPolynomial = 0x0;
  hspi3.Init.NSSPMode = SPI_NSS_PULSE_ENABLE;
  hspi3.Init.NSSPolarity = SPI_NSS_POLARITY_LOW;
  hspi3.Init.FifoThreshold = SPI_FIFO_THRESHOLD_01DATA;
  hspi3.Init.TxCRCInitializationPattern = SPI_CRC_INITIALIZATION_ALL_ZERO_PATTERN;
  hspi3.Init.RxCRCInitializationPattern = SPI_CRC_INITIALIZATION_ALL_ZERO_PATTERN;
  hspi3.Init.MasterSSIdleness = SPI_MASTER_SS_IDLENESS_00CYCLE;
  hspi3.Init.MasterInterDataIdleness = SPI_MASTER_INTERDATA_IDLENESS_00CYCLE;
  hspi3.Init.MasterReceiverAutoSusp = SPI_MASTER_RX_AUTOSUSP_DISABLE;
  hspi3.Init.MasterKeepIOState = SPI_MASTER_KEEP_IO_STATE_DISABLE;
  hspi3.Init.IOSwap = SPI_IO_SWAP_DISABLE;
  if (HAL_SPI_Init(&hspi3) != HAL_OK)
  {
    Error_Handler();
  }

}

static void MX_TIM6_Init(void)
{

  TIM_MasterConfigTypeDef sMasterConfig = {0};

  htim6.Instance = TIM6;
  htim6.Init.Prescaler = 511;
  htim6.Init.CounterMode = TIM_COUNTERMODE_UP;
  htim6.Init.Period = 2684;
  htim6.Init.AutoReloadPreload = TIM_AUTORELOAD_PRELOAD_DISABLE;
  if (HAL_TIM_Base_Init(&htim6) != HAL_OK)
  {
    Error_Handler();
  }
  sMasterConfig.MasterOutputTrigger = TIM_TRGO_RESET;
  sMasterConfig.MasterSlaveMode = TIM_MASTERSLAVEMODE_DISABLE;
  if (HAL_TIMEx_MasterConfigSynchronization(&htim6, &sMasterConfig) != HAL_OK)
  {
    Error_Handler();
  }

}

static void MX_TIM7_Init(void)
{

  TIM_MasterConfigTypeDef sMasterConfig = {0};

  htim7.Instance = TIM7;
  htim7.Init.Prescaler = 178;
  htim7.Init.CounterMode = TIM_COUNTERMODE_UP;
  htim7.Init.Period = 15;
  htim7.Init.AutoReloadPreload = TIM_AUTORELOAD_PRELOAD_DISABLE;
  if (HAL_TIM_Base_Init(&htim7) != HAL_OK)
  {
    Error_Handler();
  }
  sMasterConfig.MasterOutputTrigger = TIM_TRGO_RESET;
  sMasterConfig.MasterSlaveMode = TIM_MASTERSLAVEMODE_DISABLE;
  if (HAL_TIMEx_MasterConfigSynchronization(&htim7, &sMasterConfig) != HAL_OK)
  {
    Error_Handler();
  }

}

static void MX_TIM16_Init(void)
{

  htim16.Instance = TIM16;
  htim16.Init.Prescaler = 178;
  htim16.Init.CounterMode = TIM_COUNTERMODE_UP;
  htim16.Init.Period = 61;
  htim16.Init.ClockDivision = TIM_CLOCKDIVISION_DIV1;
  htim16.Init.RepetitionCounter = 0;
  htim16.Init.AutoReloadPreload = TIM_AUTORELOAD_PRELOAD_DISABLE;
  if (HAL_TIM_Base_Init(&htim16) != HAL_OK)
  {
    Error_Handler();
  }
  if (HAL_TIM_OnePulse_Init(&htim16, TIM_OPMODE_SINGLE) != HAL_OK)
  {
    Error_Handler();
  }

}

static void MX_TIM17_Init(void)
{

  htim17.Instance = TIM17;
  htim17.Init.Prescaler = 178;
  htim17.Init.CounterMode = TIM_COUNTERMODE_UP;
  htim17.Init.Period = 15;
  htim17.Init.ClockDivision = TIM_CLOCKDIVISION_DIV1;
  htim17.Init.RepetitionCounter = 0;
  htim17.Init.AutoReloadPreload = TIM_AUTORELOAD_PRELOAD_DISABLE;
  if (HAL_TIM_Base_Init(&htim17) != HAL_OK)
  {
    Error_Handler();
  }

}

static void MX_UART4_Init(void)
{

  huart4.Instance = UART4;
  huart4.Init.BaudRate = 115200;
  huart4.Init.WordLength = UART_WORDLENGTH_8B;
  huart4.Init.StopBits = UART_STOPBITS_1;
  huart4.Init.Parity = UART_PARITY_NONE;
  huart4.Init.Mode = UART_MODE_TX_RX;
  huart4.Init.HwFlowCtl = UART_HWCONTROL_NONE;
  huart4.Init.OverSampling = UART_OVERSAMPLING_16;
  huart4.Init.OneBitSampling = UART_ONE_BIT_SAMPLE_DISABLE;
  huart4.Init.ClockPrescaler = UART_PRESCALER_DIV1;
  huart4.AdvancedInit.AdvFeatureInit = UART_ADVFEATURE_NO_INIT;
  if (HAL_UART_Init(&huart4) != HAL_OK)
  {
    Error_Handler();
  }
  if (HAL_UARTEx_SetTxFifoThreshold(&huart4, UART_TXFIFO_THRESHOLD_1_8) != HAL_OK)
  {
    Error_Handler();
  }
  if (HAL_UARTEx_SetRxFifoThreshold(&huart4, UART_RXFIFO_THRESHOLD_1_8) != HAL_OK)
  {
    Error_Handler();
  }
  if (HAL_UARTEx_DisableFifoMode(&huart4) != HAL_OK)
  {
    Error_Handler();
  }

}

static void MX_UART7_Init(void)
{

  huart7.Instance = UART7;
  huart7.Init.BaudRate = 31250;
  huart7.Init.WordLength = UART_WORDLENGTH_8B;
  huart7.Init.StopBits = UART_STOPBITS_1;
  huart7.Init.Parity = UART_PARITY_NONE;
  huart7.Init.Mode = UART_MODE_RX;
  huart7.Init.HwFlowCtl = UART_HWCONTROL_NONE;
  huart7.Init.OverSampling = UART_OVERSAMPLING_8;
  huart7.Init.OneBitSampling = UART_ONE_BIT_SAMPLE_ENABLE;
  huart7.Init.ClockPrescaler = UART_PRESCALER_DIV2;
  huart7.AdvancedInit.AdvFeatureInit = UART_ADVFEATURE_NO_INIT;
  if (HAL_UART_Init(&huart7) != HAL_OK)
  {
    Error_Handler();
  }
  if (HAL_UARTEx_SetTxFifoThreshold(&huart7, UART_TXFIFO_THRESHOLD_1_8) != HAL_OK)
  {
    Error_Handler();
  }
  if (HAL_UARTEx_SetRxFifoThreshold(&huart7, UART_RXFIFO_THRESHOLD_1_8) != HAL_OK)
  {
    Error_Handler();
  }
  if (HAL_UARTEx_DisableFifoMode(&huart7) != HAL_OK)
  {
    Error_Handler();
  }

}

static void MX_USART10_UART_Init(void)
{

  huart10.Instance = USART10;
  huart10.Init.BaudRate = 115200;
  huart10.Init.WordLength = UART_WORDLENGTH_8B;
  huart10.Init.StopBits = UART_STOPBITS_1;
  huart10.Init.Parity = UART_PARITY_NONE;
  huart10.Init.Mode = UART_MODE_TX_RX;
  huart10.Init.HwFlowCtl = UART_HWCONTROL_NONE;
  huart10.Init.OverSampling = UART_OVERSAMPLING_16;
  huart10.Init.OneBitSampling = UART_ONE_BIT_SAMPLE_DISABLE;
  huart10.Init.ClockPrescaler = UART_PRESCALER_DIV1;
  huart10.AdvancedInit.AdvFeatureInit = UART_ADVFEATURE_NO_INIT;
  if (HAL_UART_Init(&huart10) != HAL_OK)
  {
    Error_Handler();
  }
  if (HAL_UARTEx_SetTxFifoThreshold(&huart10, UART_TXFIFO_THRESHOLD_1_8) != HAL_OK)
  {
    Error_Handler();
  }
  if (HAL_UARTEx_SetRxFifoThreshold(&huart10, UART_RXFIFO_THRESHOLD_1_8) != HAL_OK)
  {
    Error_Handler();
  }
  if (HAL_UARTEx_DisableFifoMode(&huart10) != HAL_OK)
  {
    Error_Handler();
  }

}

static void MX_DMA_Init(void)
{

  /* DMA controller clock enable */
  __HAL_RCC_DMA1_CLK_ENABLE();
  __HAL_RCC_DMA2_CLK_ENABLE();

  /* Configure DMA request hdma_memtomem_dma1_stream0 on DMA1_Stream0 */
  hdma_memtomem_dma1_stream0.Instance = DMA1_Stream0;
  hdma_memtomem_dma1_stream0.Init.Request = DMA_REQUEST_MEM2MEM;
  hdma_memtomem_dma1_stream0.Init.Direction = DMA_MEMORY_TO_MEMORY;
  hdma_memtomem_dma1_stream0.Init.PeriphInc = DMA_PINC_ENABLE;
  hdma_memtomem_dma1_stream0.Init.MemInc = DMA_MINC_ENABLE;
  hdma_memtomem_dma1_stream0.Init.PeriphDataAlignment = DMA_PDATAALIGN_BYTE;
  hdma_memtomem_dma1_stream0.Init.MemDataAlignment = DMA_MDATAALIGN_BYTE;
  hdma_memtomem_dma1_stream0.Init.Mode = DMA_NORMAL;
  hdma_memtomem_dma1_stream0.Init.Priority = DMA_PRIORITY_MEDIUM;
  hdma_memtomem_dma1_stream0.Init.FIFOMode = DMA_FIFOMODE_ENABLE;
  hdma_memtomem_dma1_stream0.Init.FIFOThreshold = DMA_FIFO_THRESHOLD_HALFFULL;
  hdma_memtomem_dma1_stream0.Init.MemBurst = DMA_MBURST_SINGLE;
  hdma_memtomem_dma1_stream0.Init.PeriphBurst = DMA_PBURST_SINGLE;
  if (HAL_DMA_Init(&hdma_memtomem_dma1_stream0) != HAL_OK)
  {
    Error_Handler( );
  }

  /* Configure DMA request hdma_memtomem_dma1_stream3 on DMA1_Stream3 */
  hdma_memtomem_dma1_stream3.Instance = DMA1_Stream3;
  hdma_memtomem_dma1_stream3.Init.Request = DMA_REQUEST_MEM2MEM;
  hdma_memtomem_dma1_stream3.Init.Direction = DMA_MEMORY_TO_MEMORY;
  hdma_memtomem_dma1_stream3.Init.PeriphInc = DMA_PINC_ENABLE;
  hdma_memtomem_dma1_stream3.Init.MemInc = DMA_MINC_ENABLE;
  hdma_memtomem_dma1_stream3.Init.PeriphDataAlignment = DMA_PDATAALIGN_BYTE;
  hdma_memtomem_dma1_stream3.Init.MemDataAlignment = DMA_MDATAALIGN_BYTE;
  hdma_memtomem_dma1_stream3.Init.Mode = DMA_NORMAL;
  hdma_memtomem_dma1_stream3.Init.Priority = DMA_PRIORITY_MEDIUM;
  hdma_memtomem_dma1_stream3.Init.FIFOMode = DMA_FIFOMODE_ENABLE;
  hdma_memtomem_dma1_stream3.Init.FIFOThreshold = DMA_FIFO_THRESHOLD_HALFFULL;
  hdma_memtomem_dma1_stream3.Init.MemBurst = DMA_MBURST_SINGLE;
  hdma_memtomem_dma1_stream3.Init.PeriphBurst = DMA_PBURST_SINGLE;
  if (HAL_DMA_Init(&hdma_memtomem_dma1_stream3) != HAL_OK)
  {
    Error_Handler( );
  }

  /* DMA interrupt init */
  /* DMA1_Stream1_IRQn interrupt configuration */
  HAL_NVIC_SetPriority(DMA1_Stream1_IRQn, 3, 0);
  HAL_NVIC_EnableIRQ(DMA1_Stream1_IRQn);
  /* DMA1_Stream2_IRQn interrupt configuration */
  HAL_NVIC_SetPriority(DMA1_Stream2_IRQn, 3, 0);
  HAL_NVIC_EnableIRQ(DMA1_Stream2_IRQn);
  /* DMA1_Stream4_IRQn interrupt configuration */
  HAL_NVIC_SetPriority(DMA1_Stream4_IRQn, 0, 0);
  HAL_NVIC_EnableIRQ(DMA1_Stream4_IRQn);
  /* DMA1_Stream5_IRQn interrupt configuration */
  HAL_NVIC_SetPriority(DMA1_Stream5_IRQn, 0, 0);
  HAL_NVIC_EnableIRQ(DMA1_Stream5_IRQn);
  /* DMA2_Stream6_IRQn interrupt configuration */
  HAL_NVIC_SetPriority(DMA2_Stream6_IRQn, 0, 0);
  HAL_NVIC_EnableIRQ(DMA2_Stream6_IRQn);

}

/**
  * Enable MDMA controller clock
  * Configure MDMA for global transfers
  *   hmdma_mdma_channel40_dma1_stream0_tc_0
  *   node_mdma_channel40_dma1_stream3_tc_1
  */
static void MX_MDMA_Init(void)
{

  /* MDMA controller clock enable */
  __HAL_RCC_MDMA_CLK_ENABLE();
  /* Local variables */
  MDMA_LinkNodeConfTypeDef nodeConfig;

  /* Configure MDMA channel MDMA_Channel0 */
  /* Configure MDMA request hmdma_mdma_channel40_dma1_stream0_tc_0 on MDMA_Channel0 */
  hmdma_mdma_channel40_dma1_stream0_tc_0.Instance = MDMA_Channel0;
  hmdma_mdma_channel40_dma1_stream0_tc_0.Init.Request = MDMA_REQUEST_DMA1_Stream0_TC;
  hmdma_mdma_channel40_dma1_stream0_tc_0.Init.TransferTriggerMode = MDMA_BUFFER_TRANSFER;
  hmdma_mdma_channel40_dma1_stream0_tc_0.Init.Priority = MDMA_PRIORITY_LOW;
  hmdma_mdma_channel40_dma1_stream0_tc_0.Init.Endianness = MDMA_LITTLE_ENDIANNESS_PRESERVE;
  hmdma_mdma_channel40_dma1_stream0_tc_0.Init.SourceInc = MDMA_SRC_INC_BYTE;
  hmdma_mdma_channel40_dma1_stream0_tc_0.Init.DestinationInc = MDMA_DEST_INC_BYTE;
  hmdma_mdma_channel40_dma1_stream0_tc_0.Init.SourceDataSize = MDMA_SRC_DATASIZE_BYTE;
  hmdma_mdma_channel40_dma1_stream0_tc_0.Init.DestDataSize = MDMA_DEST_DATASIZE_BYTE;
  hmdma_mdma_channel40_dma1_stream0_tc_0.Init.DataAlignment = MDMA_DATAALIGN_PACKENABLE;
  hmdma_mdma_channel40_dma1_stream0_tc_0.Init.BufferTransferLength = 1;
  hmdma_mdma_channel40_dma1_stream0_tc_0.Init.SourceBurst = MDMA_SOURCE_BURST_SINGLE;
  hmdma_mdma_channel40_dma1_stream0_tc_0.Init.DestBurst = MDMA_DEST_BURST_SINGLE;
  hmdma_mdma_channel40_dma1_stream0_tc_0.Init.SourceBlockAddressOffset = 0;
  hmdma_mdma_channel40_dma1_stream0_tc_0.Init.DestBlockAddressOffset = 0;
  if (HAL_MDMA_Init(&hmdma_mdma_channel40_dma1_stream0_tc_0) != HAL_OK)
  {
    Error_Handler();
  }

  /* Configure post request address and data masks */
  if (HAL_MDMA_ConfigPostRequestMask(&hmdma_mdma_channel40_dma1_stream0_tc_0, 0, 0) != HAL_OK)
  {
    Error_Handler();
  }

  /* Initialize MDMA link node according to specified parameters */
  nodeConfig.Init.Request = MDMA_REQUEST_DMA1_Stream3_TC;
  nodeConfig.Init.TransferTriggerMode = MDMA_BUFFER_TRANSFER;
  nodeConfig.Init.Priority = MDMA_PRIORITY_LOW;
  nodeConfig.Init.Endianness = MDMA_LITTLE_ENDIANNESS_PRESERVE;
  nodeConfig.Init.SourceInc = MDMA_SRC_INC_BYTE;
  nodeConfig.Init.DestinationInc = MDMA_DEST_INC_BYTE;
  nodeConfig.Init.SourceDataSize = MDMA_SRC_DATASIZE_BYTE;
  nodeConfig.Init.DestDataSize = MDMA_DEST_DATASIZE_BYTE;
  nodeConfig.Init.DataAlignment = MDMA_DATAALIGN_PACKENABLE;
  nodeConfig.Init.BufferTransferLength = 1;
  nodeConfig.Init.SourceBurst = MDMA_SOURCE_BURST_SINGLE;
  nodeConfig.Init.DestBurst = MDMA_DEST_BURST_SINGLE;
  nodeConfig.Init.SourceBlockAddressOffset = 0;
  nodeConfig.Init.DestBlockAddressOffset = 0;
  nodeConfig.PostRequestMaskAddress = 0;
  nodeConfig.PostRequestMaskData = 0;
  nodeConfig.SrcAddress = 0;
  nodeConfig.DstAddress = 0;
  nodeConfig.BlockDataLength = 0;
  nodeConfig.BlockCount = 0;
  if (HAL_MDMA_LinkedList_CreateNode(&node_mdma_channel40_dma1_stream3_tc_1, &nodeConfig) != HAL_OK)
  {
    Error_Handler();
  }

  /* Connect a node to the linked list */
  if (HAL_MDMA_LinkedList_AddNode(&hmdma_mdma_channel40_dma1_stream0_tc_0, &node_mdma_channel40_dma1_stream3_tc_1, 0) != HAL_OK)
  {
    Error_Handler();
  }

  /* MDMA interrupt initialization */
  /* MDMA_IRQn interrupt configuration */
  HAL_NVIC_SetPriority(MDMA_IRQn, 0, 0);
  HAL_NVIC_EnableIRQ(MDMA_IRQn);

}

static void MX_GPIO_Init(void)
{
  GPIO_InitTypeDef GPIO_InitStruct = {0};

  /* GPIO Ports Clock Enable */
  __HAL_RCC_GPIOE_CLK_ENABLE();
  __HAL_RCC_GPIOF_CLK_ENABLE();
  __HAL_RCC_GPIOH_CLK_ENABLE();
  __HAL_RCC_GPIOA_CLK_ENABLE();
  __HAL_RCC_GPIOB_CLK_ENABLE();
  __HAL_RCC_GPIOC_CLK_ENABLE();
  __HAL_RCC_GPIOG_CLK_ENABLE();

  /*Configure GPIO pin Output Level */
  HAL_GPIO_WritePin(GPIOF, GPIO_PIN_1, GPIO_PIN_RESET);

  /*Configure GPIO pin Output Level */
  HAL_GPIO_WritePin(GPIOG, GPIO_PIN_9|GPIO_PIN_10, GPIO_PIN_RESET);

  /*Configure GPIO pin Output Level */
  HAL_GPIO_WritePin(GPIOB, GPIO_PIN_4|GPIO_PIN_5|GPIO_PIN_7, GPIO_PIN_RESET);

  /*Configure GPIO pin : PF1 */
  GPIO_InitStruct.Pin = GPIO_PIN_1;
  GPIO_InitStruct.Mode = GPIO_MODE_OUTPUT_PP;
  GPIO_InitStruct.Pull = GPIO_NOPULL;
  GPIO_InitStruct.Speed = GPIO_SPEED_FREQ_LOW;
  HAL_GPIO_Init(GPIOF, &GPIO_InitStruct);

  /*Configure GPIO pins : PF2 PF3 PF4 PF5 */
  GPIO_InitStruct.Pin = GPIO_PIN_2|GPIO_PIN_3|GPIO_PIN_4|GPIO_PIN_5;
  GPIO_InitStruct.Mode = GPIO_MODE_INPUT;
  GPIO_InitStruct.Pull = GPIO_NOPULL;
  HAL_GPIO_Init(GPIOF, &GPIO_InitStruct);

  /*Configure GPIO pins : PG9 PG10 */
  GPIO_InitStruct.Pin = GPIO_PIN_9|GPIO_PIN_10;
  GPIO_InitStruct.Mode = GPIO_MODE_OUTPUT_PP;
  GPIO_InitStruct.Pull = GPIO_NOPULL;
  GPIO_InitStruct.Speed = GPIO_SPEED_FREQ_LOW;
  HAL_GPIO_Init(GPIOG, &GPIO_InitStruct);

  /*Configure GPIO pin : PB4 */
  GPIO_InitStruct.Pin = GPIO_PIN_4;
  GPIO_InitStruct.Mode = GPIO_MODE_OUTPUT_PP;
  GPIO_InitStruct.Pull = GPIO_PULLDOWN;
  GPIO_InitStruct.Speed = GPIO_SPEED_FREQ_LOW;
  HAL_GPIO_Init(GPIOB, &GPIO_InitStruct);

  /*Configure GPIO pins : PB5 PB7 */
  GPIO_InitStruct.Pin = GPIO_PIN_5|GPIO_PIN_7;
  GPIO_InitStruct.Mode = GPIO_MODE_OUTPUT_PP;
  GPIO_InitStruct.Pull = GPIO_NOPULL;
  GPIO_InitStruct.Speed = GPIO_SPEED_FREQ_LOW;
  HAL_GPIO_Init(GPIOB, &GPIO_InitStruct);

  /*Configure GPIO pin : PB6 */
  GPIO_InitStruct.Pin = GPIO_PIN_6;
  GPIO_InitStruct.Mode = GPIO_MODE_INPUT;
  GPIO_InitStruct.Pull = GPIO_NOPULL;
  HAL_GPIO_Init(GPIOB, &GPIO_InitStruct);

  /*Configure GPIO pin : PE1 */
  GPIO_InitStruct.Pin = GPIO_PIN_1;
  GPIO_InitStruct.Mode = GPIO_MODE_INPUT;
  GPIO_InitStruct.Pull = GPIO_NOPULL;
  HAL_GPIO_Init(GPIOE, &GPIO_InitStruct);

}

void Error_Handler(void)
{
}
